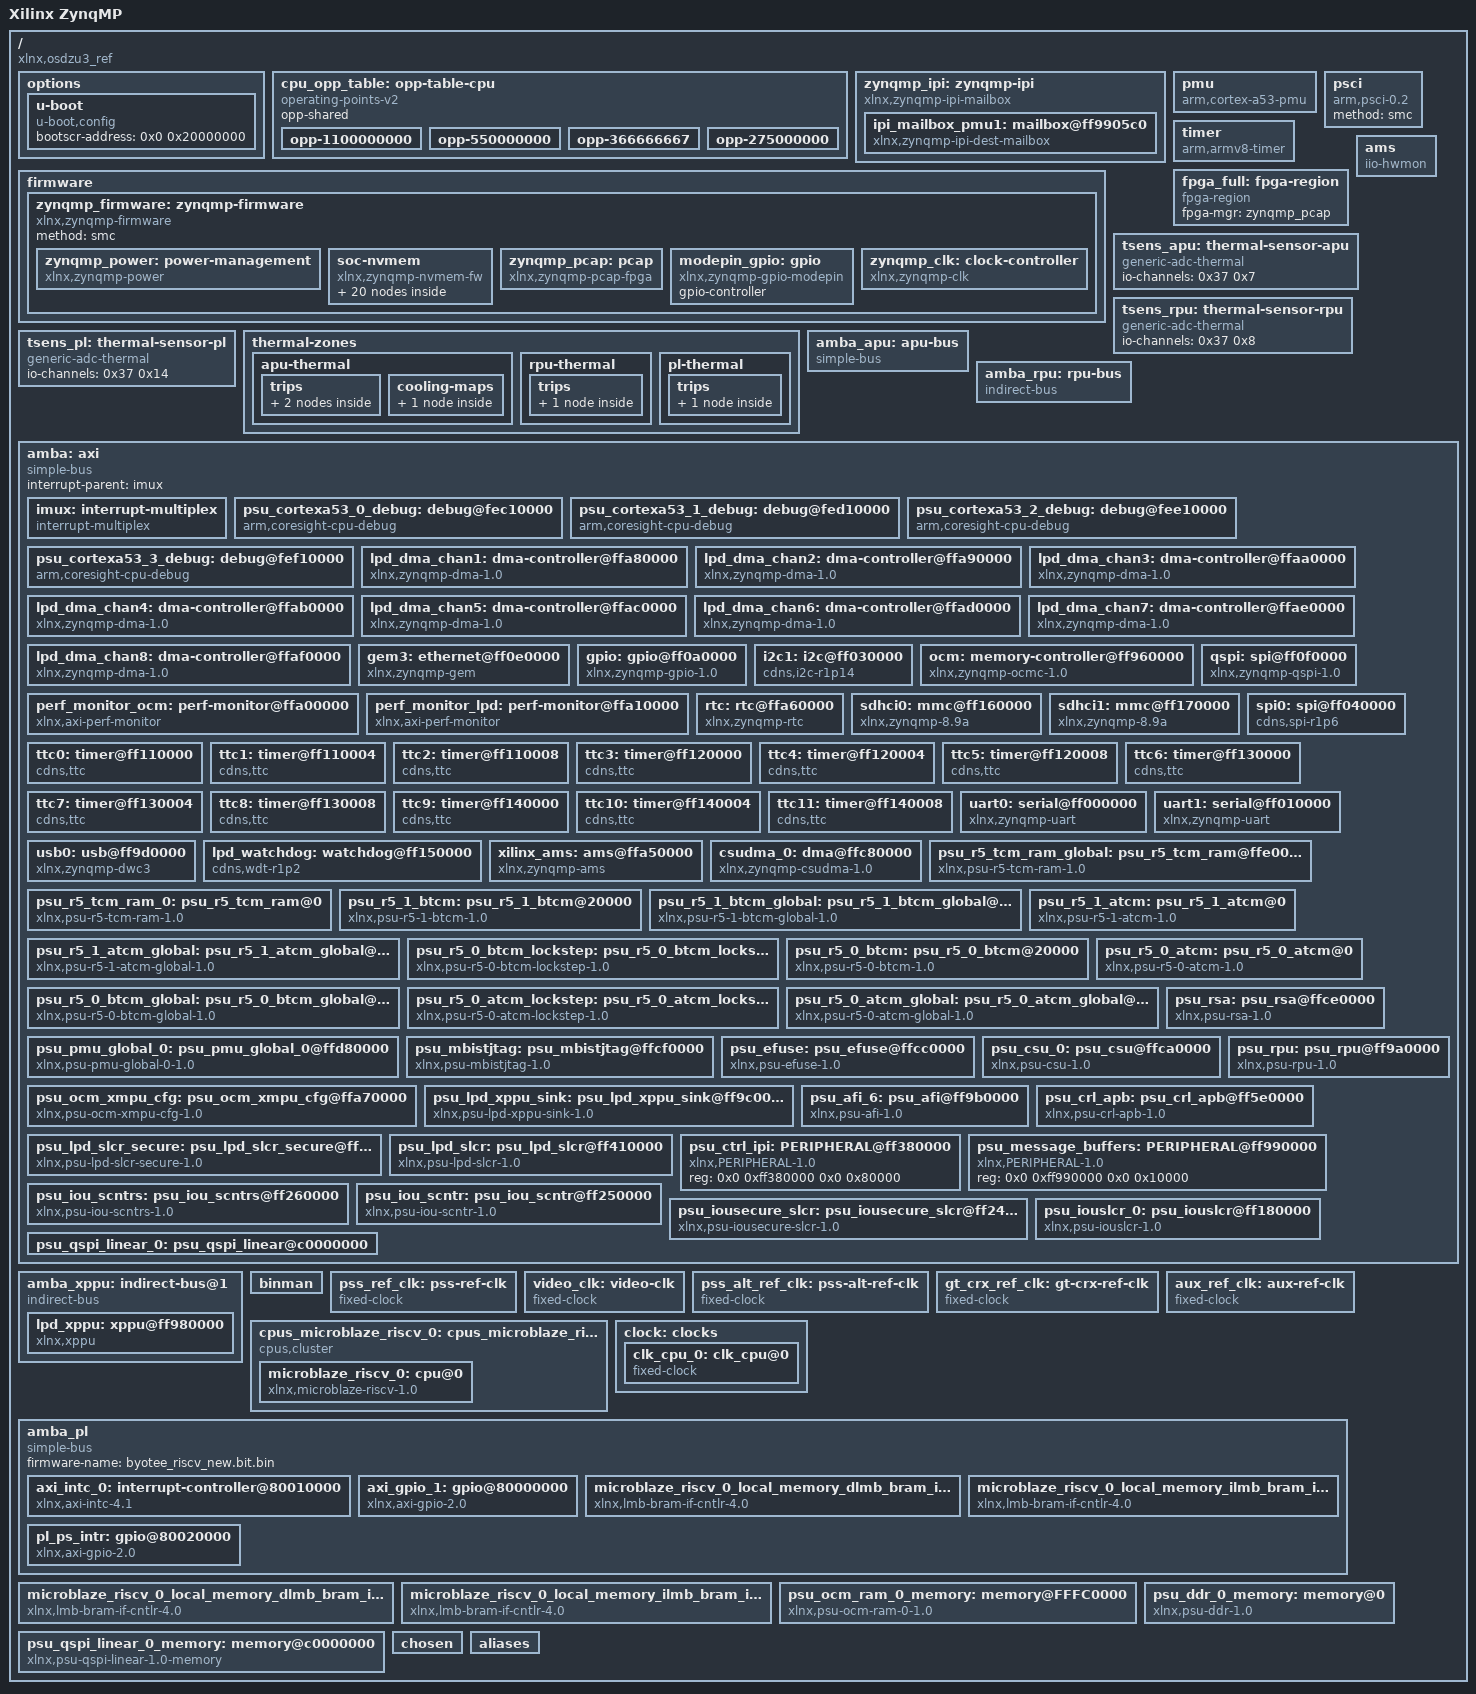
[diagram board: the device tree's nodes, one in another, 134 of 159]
/dts-v1/;
/ {
        compatible = "xlnx,osdzu3_ref";
        #address-cells = <0x2>;
        #size-cells = <0x2>;
        model = "Xilinx ZynqMP";
        board = "osdzu3_ref";
        device_id = "xczu3eg";
        slrcount = <0x1>;
        family = "ZynqMP";
        speed_grade = "1";
        pruned-sdt = <0x1>;

        options {

                u-boot {
                        compatible = "u-boot,config";
                        bootscr-address = <0x0 0x20000000>;
                };
        };

        cpu_opp_table: opp-table-cpu {
                compatible = "operating-points-v2";
                opp-shared;
                phandle = <0x70>;

                opp-1100000000 {
                        opp-hz = <0x0 0x4190ab00>;
                        clock-latency-ns = <0x7a120>;
                        opp-microvolt = <0xf4240>;
                };

                opp-550000000 {
                        opp-hz = <0x0 0x20c85580>;
                        clock-latency-ns = <0x7a120>;
                        opp-microvolt = <0xf4240>;
                };

                opp-366666667 {
                        opp-hz = <0x0 0x15dae3ab>;
                        clock-latency-ns = <0x7a120>;
                        opp-microvolt = <0xf4240>;
                };

                opp-275000000 {
                        opp-hz = <0x0 0x10642ac0>;
                        clock-latency-ns = <0x7a120>;
                        opp-microvolt = <0xf4240>;
                };
        };

        zynqmp_ipi: zynqmp-ipi {
                bootph-all;
                compatible = "xlnx,zynqmp-ipi-mailbox";
                interrupt-parent = <&imux>;
                interrupts = <0x0 0x23 0x4>;
                xlnx,ipi-id = <0x0>;
                #address-cells = <0x2>;
                #size-cells = <0x2>;
                ranges;
                phandle = <0xa8>;

                ipi_mailbox_pmu1: mailbox@ff9905c0 {
                        bootph-all;
                        compatible = "xlnx,zynqmp-ipi-dest-mailbox";
                        reg = <0x0 0xff9905c0 0x0 0x20 0x0 0xff9905e0 0x0 0x20 0x0 0xff990e80 0x0 0x20 0x0 0xff990ea0 0x0 0x20>;
                        reg-names = "local_request_region", "local_response_region", "remote_request_region", "remote_response_region";
                        #mbox-cells = <0x1>;
                        xlnx,ipi-id = <0x4>;
                        phandle = <0x8b>;
                };
        };

        pmu {
                compatible = "arm,cortex-a53-pmu";
                interrupt-parent = <&imux>;
                interrupts = <0x0 0x8f 0x4 0x0 0x90 0x4 0x0 0x91 0x4 0x0 0x92 0x4>;
        };

        psci {
                compatible = "arm,psci-0.2";
                method = "smc";
        };

        firmware {

                zynqmp_firmware: zynqmp-firmware {
                        compatible = "xlnx,zynqmp-firmware";
                        #power-domain-cells = <0x1>;
                        method = "smc";
                        bootph-all;
                        phandle = <0x7b>;

                        zynqmp_power: power-management {
                                bootph-all;
                                compatible = "xlnx,zynqmp-power";
                                interrupt-parent = <&imux>;
                                interrupts = <0x0 0x23 0x4>;
                                mboxes = <0x8b 0x0 0x8b 0x1>;
                                mbox-names = "tx", "rx";
                                phandle = <0xaa>;
                        };

                        soc-nvmem {
                                compatible = "xlnx,zynqmp-nvmem-fw";

                                nvmem-layout {
                                        compatible = "fixed-layout";
                                        #address-cells = <0x1>;
                                        #size-cells = <0x1>;

                                        soc_revision: soc-revision@0 {
                                                reg = <0x0 0x4>;
                                                phandle = <0xab>;
                                        };

                                        efuse_dna: efuse-dna@c {
                                                reg = <0xc 0xc>;
                                                phandle = <0xac>;
                                        };

                                        efuse_usr0: efuse-usr0@20 {
                                                reg = <0x20 0x4>;
                                                phandle = <0xad>;
                                        };

                                        efuse_usr1: efuse-usr1@24 {
                                                reg = <0x24 0x4>;
                                                phandle = <0xae>;
                                        };

                                        efuse_usr2: efuse-usr2@28 {
                                                reg = <0x28 0x4>;
                                                phandle = <0xaf>;
                                        };

                                        efuse_usr3: efuse-usr3@2c {
                                                reg = <0x2c 0x4>;
                                                phandle = <0xb0>;
                                        };

                                        efuse_usr4: efuse-usr4@30 {
                                                reg = <0x30 0x4>;
                                                phandle = <0xb1>;
                                        };

                                        efuse_usr5: efuse-usr5@34 {
                                                reg = <0x34 0x4>;
                                                phandle = <0xb2>;
                                        };

                                        efuse_usr6: efuse-usr6@38 {
                                                reg = <0x38 0x4>;
                                                phandle = <0xb3>;
                                        };

                                        efuse_usr7: efuse-usr7@3c {
                                                reg = <0x3c 0x4>;
                                                phandle = <0xb4>;
                                        };

                                        efuse_miscusr: efuse-miscusr@40 {
                                                reg = <0x40 0x4>;
                                                phandle = <0xb5>;
                                        };

                                        efuse_chash: efuse-chash@50 {
                                                reg = <0x50 0x4>;
                                                phandle = <0xb6>;
                                        };

                                        efuse_pufmisc: efuse-pufmisc@54 {
                                                reg = <0x54 0x4>;
                                                phandle = <0xb7>;
                                        };

                                        efuse_sec: efuse-sec@58 {
                                                reg = <0x58 0x4>;
                                                phandle = <0xb8>;
                                        };

                                        efuse_spkid: efuse-spkid@5c {
                                                reg = <0x5c 0x4>;
                                                phandle = <0xb9>;
                                        };

                                        efuse_aeskey: efuse-aeskey@60 {
                                                reg = <0x60 0x20>;
                                                phandle = <0xba>;
                                        };

                                        efuse_ppk0hash: efuse-ppk0hash@a0 {
                                                reg = <0xa0 0x30>;
                                                phandle = <0xbb>;
                                        };

                                        efuse_ppk1hash: efuse-ppk1hash@d0 {
                                                reg = <0xd0 0x30>;
                                                phandle = <0xbc>;
                                        };

                                        efuse_pufuser: efuse-pufuser@100 {
                                                reg = <0x100 0x7f>;
                                                phandle = <0xbd>;
                                        };
                                };
                        };

                        zynqmp_pcap: pcap {
                                compatible = "xlnx,zynqmp-pcap-fpga";
                                phandle = <0x91>;
                        };

                        modepin_gpio: gpio {
                                compatible = "xlnx,zynqmp-gpio-modepin";
                                gpio-controller;
                                #gpio-cells = <0x2>;
                                phandle = <0x98>;
                        };

                        zynqmp_clk: clock-controller {
                                bootph-all;
                                #clock-cells = <0x1>;
                                compatible = "xlnx,zynqmp-clk";
                                clocks = <&pss_ref_clk>,
                                 <&video_clk>,
                                 <&pss_alt_ref_clk>,
                                 <&aux_ref_clk>,
                                 <&gt_crx_ref_clk>;
                                clock-names = "pss_ref_clk", "video_clk", "pss_alt_ref_clk", "aux_ref_clk", "gt_crx_ref_clk";
                                phandle = <0x73>;
                        };
                };
        };

        timer {
                compatible = "arm,armv8-timer";
                interrupt-parent = <&imux>;
                interrupts = <0x1 0xd 0xf08 0x1 0xe 0xf08 0x1 0xb 0xf08 0x1 0xa 0xf08>;
        };

        fpga_full: fpga-region {
                compatible = "fpga-region";
                fpga-mgr = <&zynqmp_pcap>;
                #address-cells = <0x2>;
                #size-cells = <0x2>;
                ranges;
                phandle = <0xbe>;
        };

        ams {
                compatible = "iio-hwmon";
                io-channels = <0x37 0x0 0x37 0x1 0x37 0x2 0x37 0x3 0x37 0x4 0x37 0x5 0x37 0x6 0x37 0x7 0x37 0x8 0x37 0x9 0x37 0xa 0x37 0xb 0x37 0xc 0x37 0xd 0x37 0xe 0x37 0xf 0x37 0x10 0x37 0x11 0x37 0x12 0x37 0x13 0x37 0x14 0x37 0x15 0x37 0x16 0x37 0x17 0x37 0x18 0x37 0x19 0x37 0x1a 0x37 0x1b 0x37 0x1c 0x37 0x1d>;
        };

        tsens_apu: thermal-sensor-apu {
                compatible = "generic-adc-thermal";
                #thermal-sensor-cells = <0x0>;
                io-channels = <0x37 0x7>;
                io-channel-names = "sensor-channel";
                phandle = <0x92>;
        };

        tsens_rpu: thermal-sensor-rpu {
                compatible = "generic-adc-thermal";
                #thermal-sensor-cells = <0x0>;
                io-channels = <0x37 0x8>;
                io-channel-names = "sensor-channel";
                phandle = <0x94>;
        };

        tsens_pl: thermal-sensor-pl {
                compatible = "generic-adc-thermal";
                #thermal-sensor-cells = <0x0>;
                io-channels = <0x37 0x14>;
                io-channel-names = "sensor-channel";
                phandle = <0x95>;
        };

        thermal-zones {

                apu-thermal {
                        polling-delay-passive = <0x3e8>;
                        polling-delay = <0x1388>;
                        thermal-sensors = <0x92>;

                        trips {

                                apu_passive: passive {
                                        temperature = <0x16b48>;
                                        hysteresis = <0xdac>;
                                        type = "passive";
                                        phandle = <0x93>;
                                };

                                apu_critical: critical {
                                        temperature = <0x178f4>;
                                        hysteresis = <0xdac>;
                                        type = "critical";
                                        phandle = <0xbf>;
                                };
                        };

                        cooling-maps {

                                map {
                                        trip = <0x93>;
                                        cooling-device = <0x87 0xffffffff 0xffffffff 0x88 0xffffffff 0xffffffff 0x89 0xffffffff 0xffffffff 0x8a 0xffffffff 0xffffffff>;
                                };
                        };
                };

                rpu-thermal {
                        polling-delay = <0x2710>;
                        thermal-sensors = <0x94>;

                        trips {

                                critical {
                                        temperature = <0x178f4>;
                                        hysteresis = <0xdac>;
                                        type = "critical";
                                };
                        };
                };

                pl-thermal {
                        polling-delay = <0x2710>;
                        thermal-sensors = <0x95>;

                        trips {

                                critical {
                                        temperature = <0x178f4>;
                                        hysteresis = <0xdac>;
                                        type = "critical";
                                };
                        };
                };
        };

        amba_apu: apu-bus {
                compatible = "simple-bus";
                #address-cells = <0x2>;
                #size-cells = <0x2>;
                ranges;
                phandle = <0x2>;
        };

        amba_rpu: rpu-bus {
                compatible = "indirect-bus";
                #address-cells = <0x2>;
                #size-cells = <0x1>;
                phandle = <0x74>;
        };

        amba: axi {
                compatible = "simple-bus";
                bootph-all;
                #address-cells = <0x2>;
                #size-cells = <0x2>;
                ranges;
                interrupt-parent = <&imux>;
                phandle = <0x1>;

                imux: interrupt-multiplex {
                        compatible = "interrupt-multiplex";
                        #address-cells = <0x0>;
                        #interrupt-cells = <0x3>;
                        interrupt-controller;
                        interrupt-map-mask = <0x0 0xffff 0x0>;
                        interrupt-map = <0x0 0x17 0x0 0x41 0x0 0x17 0x1 0x0 0x18 0x0 0x41 0x0 0x18 0x1 0x0 0x7b 0x0 0x41 0x0 0x7b 0x4 0x0 0x56 0x0 0x41 0x0 0x56 0x4 0x0 0x7c 0x0 0x41 0x0 0x7c 0x4 0x0 0x7d 0x0 0x41 0x0 0x7d 0x4 0x0 0x7e 0x0 0x41 0x0 0x8e 0x4 0x0 0x7f 0x0 0x41 0x0 0x7f 0x4 0x0 0x80 0x0 0x41 0x0 0x80 0x4 0x0 0x81 0x0 0x41 0x0 0x81 0x4 0x0 0x82 0x0 0x41 0x0 0x82 0x4 0x0 0x83 0x0 0x41 0x0 0x83 0x4 0x0 0x84 0x0 0x41 0x0 0x84 0x4 0x0 0x4d 0x0 0x41 0x0 0x4d 0x4 0x0 0x4e 0x0 0x41 0x0 0x4e 0x4 0x0 0x4f 0x0 0x41 0x0 0x4f 0x4 0x0 0x50 0x0 0x41 0x0 0x50 0x4 0x0 0x51 0x0 0x41 0x0 0x51 0x4 0x0 0x52 0x0 0x41 0x0 0x52 0x4 0x0 0x53 0x0 0x41 0x0 0x53 0x4 0x0 0x54 0x0 0x41 0x0 0x54 0x4 0x0 0x70 0x0 0x41 0x0 0x70 0x4 0x0 0xe 0x0 0x41 0x0 0xe 0x4 0x0 0x39 0x0 0x41 0x0 0x39 0x4 0x0 0x3b 0x0 0x41 0x0 0x3b 0x4 0x0 0x3d 0x0 0x41 0x0 0x3d 0x4 0x0 0x3f 0x0 0x41 0x0 0x3f 0x4 0x0 0x10 0x0 0x41 0x0 0x10 0x4 0x0 0x11 0x0 0x41 0x0 0x11 0x4 0x0 0x12 0x0 0x41 0x0 0x12 0x4 0x0 0xa 0x0 0x41 0x0 0xa 0x4 0x0 0x72 0x0 0x41 0x0 0x72 0x4 0x0 0x73 0x0 0x41 0x0 0x73 0x4 0x0 0x74 0x0 0x41 0x0 0x74 0x1 0x0 0x75 0x0 0x41 0x0 0x75 0x1 0x0 0x76 0x0 0x41 0x0 0x76 0x4 0x0 0xf 0x0 0x41 0x0 0xf 0x4 0x0 0x1a 0x0 0x41 0x0 0x1a 0x4 0x0 0x1b 0x0 0x41 0x0 0x1b 0x4 0x0 0x85 0x0 0x41 0x0 0x85 0x4 0x0 0x30 0x0 0x41 0x0 0x30 0x4 0x0 0x31 0x0 0x41 0x0 0x31 0x4 0x0 0x13 0x0 0x41 0x0 0x13 0x4 0x0 0x14 0x0 0x41 0x0 0x14 0x4 0x0 0x24 0x0 0x41 0x0 0x24 0x4 0x0 0x25 0x0 0x41 0x0 0x25 0x4 0x0 0x26 0x0 0x41 0x0 0x26 0x4 0x0 0x27 0x0 0x41 0x0 0x27 0x4 0x0 0x28 0x0 0x41 0x0 0x28 0x4 0x0 0x29 0x0 0x41 0x0 0x29 0x4 0x0 0x2a 0x0 0x41 0x0 0x2a 0x4 0x0 0x2b 0x0 0x41 0x0 0x2b 0x4 0x0 0x2c 0x0 0x41 0x0 0x2c 0x4 0x0 0x2d 0x0 0x41 0x0 0x2d 0x4 0x0 0x2e 0x0 0x41 0x0 0x2e 0x4 0x0 0x2f 0x0 0x41 0x0 0x2f 0x4 0x0 0x15 0x0 0x41 0x0 0x15 0x4 0x0 0x16 0x0 0x41 0x0 0x16 0x4 0x0 0x41 0x0 0x41 0x0 0x41 0x4 0x0 0x45 0x0 0x41 0x0 0x45 0x4 0x0 0x4b 0x0 0x41 0x0 0x4b 0x4 0x0 0x46 0x0 0x41 0x0 0x46 0x4 0x0 0x4a 0x0 0x41 0x0 0x4a 0x4 0x0 0x4c 0x0 0x41 0x0 0x4c 0x4 0x0 0x35 0x0 0x41 0x0 0x35 0x4 0x0 0x71 0x0 0x41 0x0 0x71 0x4 0x0 0x77 0x0 0x41 0x0 0x77 0x4 0x0 0x1d 0x0 0x41 0x0 0x1d 0x4 0x0 0x1e 0x0 0x41 0x0 0x1e 0x4 0x0 0x1f 0x0 0x41 0x0 0x1f 0x4 0x0 0x20 0x0 0x41 0x0 0x20 0x4 0x0 0x21 0x0 0x41 0x0 0x21 0x4 0x0 0x22 0x0 0x41 0x0 0x22 0x4 0x0 0x23 0x0 0x41 0x0 0x23 0x4 0x0 0x7a 0x0 0x41 0x0 0x7a 0x4 0x0 0x17 0x0 0x7a 0x0 0x17 0x1 0x0 0x18 0x0 0x7a 0x0 0x18 0x1 0x0 0x7b 0x0 0x7a 0x0 0x7b 0x4 0x0 0x56 0x0 0x7a 0x0 0x56 0x4 0x0 0x7c 0x0 0x7a 0x0 0x7c 0x4 0x0 0x7d 0x0 0x7a 0x0 0x7d 0x4 0x0 0x7e 0x0 0x7a 0x0 0x8e 0x4 0x0 0x7f 0x0 0x7a 0x0 0x7f 0x4 0x0 0x80 0x0 0x7a 0x0 0x80 0x4 0x0 0x81 0x0 0x7a 0x0 0x81 0x4 0x0 0x82 0x0 0x7a 0x0 0x82 0x4 0x0 0x83 0x0 0x7a 0x0 0x83 0x4 0x0 0x84 0x0 0x7a 0x0 0x84 0x4 0x0 0x4d 0x0 0x7a 0x0 0x4d 0x4 0x0 0x4e 0x0 0x7a 0x0 0x4e 0x4 0x0 0x4f 0x0 0x7a 0x0 0x4f 0x4 0x0 0x50 0x0 0x7a 0x0 0x50 0x4 0x0 0x51 0x0 0x7a 0x0 0x51 0x4 0x0 0x52 0x0 0x7a 0x0 0x52 0x4 0x0 0x53 0x0 0x7a 0x0 0x53 0x4 0x0 0x54 0x0 0x7a 0x0 0x54 0x4 0x0 0x70 0x0 0x7a 0x0 0x70 0x4 0x0 0xe 0x0 0x7a 0x0 0xe 0x4 0x0 0x39 0x0 0x7a 0x0 0x39 0x4 0x0 0x3b 0x0 0x7a 0x0 0x3b 0x4 0x0 0x3d 0x0 0x7a 0x0 0x3d 0x4 0x0 0x3f 0x0 0x7a 0x0 0x3f 0x4 0x0 0x10 0x0 0x7a 0x0 0x10 0x4 0x0 0x11 0x0 0x7a 0x0 0x11 0x4 0x0 0x12 0x0 0x7a 0x0 0x12 0x4 0x0 0xa 0x0 0x7a 0x0 0xa 0x4 0x0 0x72 0x0 0x7a 0x0 0x72 0x4 0x0 0x73 0x0 0x7a 0x0 0x73 0x4 0x0 0x74 0x0 0x7a 0x0 0x74 0x1 0x0 0x75 0x0 0x7a 0x0 0x75 0x1 0x0 0x76 0x0 0x7a 0x0 0x76 0x4 0x0 0xf 0x0 0x7a 0x0 0xf 0x4 0x0 0x1a 0x0 0x7a 0x0 0x1a 0x4 0x0 0x1b 0x0 0x7a 0x0 0x1b 0x4 0x0 0x85 0x0 0x7a 0x0 0x85 0x4 0x0 0x30 0x0 0x7a 0x0 0x30 0x4 0x0 0x31 0x0 0x7a 0x0 0x31 0x4 0x0 0x13 0x0 0x7a 0x0 0x13 0x4 0x0 0x14 0x0 0x7a 0x0 0x14 0x4 0x0 0x24 0x0 0x7a 0x0 0x24 0x4 0x0 0x25 0x0 0x7a 0x0 0x25 0x4 0x0 0x26 0x0 0x7a 0x0 0x26 0x4 0x0 0x27 0x0 0x7a 0x0 0x27 0x4 0x0 0x28 0x0 0x7a 0x0 0x28 0x4 0x0 0x29 0x0 0x7a 0x0 0x29 0x4 0x0 0x2a 0x0 0x7a 0x0 0x2a 0x4 0x0 0x2b 0x0 0x7a 0x0 0x2b 0x4 0x0 0x2c 0x0 0x7a 0x0 0x2c 0x4 0x0 0x2d 0x0 0x7a 0x0 0x2d 0x4 0x0 0x2e 0x0 0x7a 0x0 0x2e 0x4 0x0 0x2f 0x0 0x7a 0x0 0x2f 0x4 0x0 0x15 0x0 0x7a 0x0 0x15 0x4 0x0 0x16 0x0 0x7a 0x0 0x16 0x4 0x0 0x41 0x0 0x7a 0x0 0x41 0x4 0x0 0x45 0x0 0x7a 0x0 0x45 0x4 0x0 0x4b 0x0 0x7a 0x0 0x4b 0x4 0x0 0x46 0x0 0x7a 0x0 0x46 0x4 0x0 0x4a 0x0 0x7a 0x0 0x4a 0x4 0x0 0x4c 0x0 0x7a 0x0 0x4c 0x4 0x0 0x35 0x0 0x7a 0x0 0x35 0x4 0x0 0x71 0x0 0x7a 0x0 0x71 0x4 0x0 0x77 0x0 0x7a 0x0 0x77 0x4 0x0 0x1d 0x0 0x7a 0x0 0x1d 0x4 0x0 0x1e 0x0 0x7a 0x0 0x1e 0x4 0x0 0x1f 0x0 0x7a 0x0 0x1f 0x4 0x0 0x20 0x0 0x7a 0x0 0x20 0x4 0x0 0x21 0x0 0x7a 0x0 0x21 0x4 0x0 0x22 0x0 0x7a 0x0 0x22 0x4 0x0 0x23 0x0 0x7a 0x0 0x23 0x4 0x0 0x7a 0x0 0x7a 0x0 0x7a 0x4>;
                        phandle = <0x86>;
                };

                psu_cortexa53_0_debug: debug@fec10000 {
                        compatible = "arm,coresight-cpu-debug", "arm,primecell";
                        reg = <0x0 0xfec10000 0x0 0x1000>;
                        clock-names = "apb_pclk";
                        cpu = <0x87>;
                        clocks = <&zynqmp_clk 0xc>;
                        phandle = <0xc3>;
                };

                psu_cortexa53_1_debug: debug@fed10000 {
                        compatible = "arm,coresight-cpu-debug", "arm,primecell";
                        reg = <0x0 0xfed10000 0x0 0x1000>;
                        clock-names = "apb_pclk";
                        cpu = <0x88>;
                        clocks = <&zynqmp_clk 0xc>;
                        phandle = <0xc4>;
                };

                psu_cortexa53_2_debug: debug@fee10000 {
                        compatible = "arm,coresight-cpu-debug", "arm,primecell";
                        reg = <0x0 0xfee10000 0x0 0x1000>;
                        clock-names = "apb_pclk";
                        cpu = <0x89>;
                        clocks = <&zynqmp_clk 0xc>;
                        phandle = <0xc5>;
                };

                psu_cortexa53_3_debug: debug@fef10000 {
                        compatible = "arm,coresight-cpu-debug", "arm,primecell";
                        reg = <0x0 0xfef10000 0x0 0x1000>;
                        clock-names = "apb_pclk";
                        cpu = <0x8a>;
                        clocks = <&zynqmp_clk 0xc>;
                        phandle = <0xc6>;
                };

                lpd_dma_chan1: dma-controller@ffa80000 {
                        status = "okay";
                        compatible = "xlnx,zynqmp-dma-1.0";
                        reg = <0x0 0xffa80000 0x0 0x1000>;
                        interrupt-parent = <&imux>;
                        interrupts = <0x0 0x4d 0x4>;
                        clock-names = "clk_main", "clk_apb";
                        #dma-cells = <0x1>;
                        xlnx,bus-width = <0x40>;
                        power-domains = <&zynqmp_firmware 0x2b>;
                        clocks = <&zynqmp_clk 0x44>,
                         <&zynqmp_clk 0x1f>;
                        xlnx,is-cache-coherent = <0x0>;
                        xlnx,ip-name = "psu_adma";
                        xlnx,dma-mode = <0x1>;
                        xlnx,dma-type = <0x1>;
                        xlnx,name = "psu_adma_0";
                        phandle = <0x34>;
                };

                lpd_dma_chan2: dma-controller@ffa90000 {
                        status = "okay";
                        compatible = "xlnx,zynqmp-dma-1.0";
                        reg = <0x0 0xffa90000 0x0 0x1000>;
                        interrupt-parent = <&imux>;
                        interrupts = <0x0 0x4e 0x4>;
                        clock-names = "clk_main", "clk_apb";
                        #dma-cells = <0x1>;
                        xlnx,bus-width = <0x40>;
                        power-domains = <&zynqmp_firmware 0x2b>;
                        clocks = <&zynqmp_clk 0x44>,
                         <&zynqmp_clk 0x1f>;
                        xlnx,is-cache-coherent = <0x0>;
                        xlnx,ip-name = "psu_adma";
                        xlnx,dma-mode = <0x1>;
                        xlnx,dma-type = <0x1>;
                        xlnx,name = "psu_adma_1";
                        phandle = <0x33>;
                };

                lpd_dma_chan3: dma-controller@ffaa0000 {
                        status = "okay";
                        compatible = "xlnx,zynqmp-dma-1.0";
                        reg = <0x0 0xffaa0000 0x0 0x1000>;
                        interrupt-parent = <&imux>;
                        interrupts = <0x0 0x4f 0x4>;
                        clock-names = "clk_main", "clk_apb";
                        #dma-cells = <0x1>;
                        xlnx,bus-width = <0x40>;
                        power-domains = <&zynqmp_firmware 0x2b>;
                        clocks = <&zynqmp_clk 0x44>,
                         <&zynqmp_clk 0x1f>;
                        xlnx,is-cache-coherent = <0x0>;
                        xlnx,ip-name = "psu_adma";
                        xlnx,dma-mode = <0x1>;
                        xlnx,dma-type = <0x1>;
                        xlnx,name = "psu_adma_2";
                        phandle = <0x32>;
                };

                lpd_dma_chan4: dma-controller@ffab0000 {
                        status = "okay";
                        compatible = "xlnx,zynqmp-dma-1.0";
                        reg = <0x0 0xffab0000 0x0 0x1000>;
                        interrupt-parent = <&imux>;
                        interrupts = <0x0 0x50 0x4>;
                        clock-names = "clk_main", "clk_apb";
                        #dma-cells = <0x1>;
                        xlnx,bus-width = <0x40>;
                        power-domains = <&zynqmp_firmware 0x2b>;
                        clocks = <&zynqmp_clk 0x44>,
                         <&zynqmp_clk 0x1f>;
                        xlnx,is-cache-coherent = <0x0>;
                        xlnx,ip-name = "psu_adma";
                        xlnx,dma-mode = <0x1>;
                        xlnx,dma-type = <0x1>;
                        xlnx,name = "psu_adma_3";
                        phandle = <0x31>;
                };

                lpd_dma_chan5: dma-controller@ffac0000 {
                        status = "okay";
                        compatible = "xlnx,zynqmp-dma-1.0";
                        reg = <0x0 0xffac0000 0x0 0x1000>;
                        interrupt-parent = <&imux>;
                        interrupts = <0x0 0x51 0x4>;
                        clock-names = "clk_main", "clk_apb";
                        #dma-cells = <0x1>;
                        xlnx,bus-width = <0x40>;
                        power-domains = <&zynqmp_firmware 0x2b>;
                        clocks = <&zynqmp_clk 0x44>,
                         <&zynqmp_clk 0x1f>;
                        xlnx,is-cache-coherent = <0x0>;
                        xlnx,ip-name = "psu_adma";
                        xlnx,dma-mode = <0x1>;
                        xlnx,dma-type = <0x1>;
                        xlnx,name = "psu_adma_4";
                        phandle = <0x30>;
                };

                lpd_dma_chan6: dma-controller@ffad0000 {
                        status = "okay";
                        compatible = "xlnx,zynqmp-dma-1.0";
                        reg = <0x0 0xffad0000 0x0 0x1000>;
                        interrupt-parent = <&imux>;
                        interrupts = <0x0 0x52 0x4>;
                        clock-names = "clk_main", "clk_apb";
                        #dma-cells = <0x1>;
                        xlnx,bus-width = <0x40>;
                        power-domains = <&zynqmp_firmware 0x2b>;
                        clocks = <&zynqmp_clk 0x44>,
                         <&zynqmp_clk 0x1f>;
                        xlnx,is-cache-coherent = <0x0>;
                        xlnx,ip-name = "psu_adma";
                        xlnx,dma-mode = <0x1>;
                        xlnx,dma-type = <0x1>;
                        xlnx,name = "psu_adma_5";
                        phandle = <0x2f>;
                };

                lpd_dma_chan7: dma-controller@ffae0000 {
                        status = "okay";
                        compatible = "xlnx,zynqmp-dma-1.0";
                        reg = <0x0 0xffae0000 0x0 0x1000>;
                        interrupt-parent = <&imux>;
                        interrupts = <0x0 0x53 0x4>;
                        clock-names = "clk_main", "clk_apb";
                        #dma-cells = <0x1>;
                        xlnx,bus-width = <0x40>;
                        power-domains = <&zynqmp_firmware 0x2b>;
                        clocks = <&zynqmp_clk 0x44>,
                         <&zynqmp_clk 0x1f>;
                        xlnx,is-cache-coherent = <0x0>;
                        xlnx,ip-name = "psu_adma";
                        xlnx,dma-mode = <0x1>;
                        xlnx,dma-type = <0x1>;
                        xlnx,name = "psu_adma_6";
                        phandle = <0x2e>;
                };

                lpd_dma_chan8: dma-controller@ffaf0000 {
                        status = "okay";
                        compatible = "xlnx,zynqmp-dma-1.0";
                        reg = <0x0 0xffaf0000 0x0 0x1000>;
                        interrupt-parent = <&imux>;
                        interrupts = <0x0 0x54 0x4>;
                        clock-names = "clk_main", "clk_apb";
                        #dma-cells = <0x1>;
                        xlnx,bus-width = <0x40>;
                        power-domains = <&zynqmp_firmware 0x2b>;
                        clocks = <&zynqmp_clk 0x44>,
                         <&zynqmp_clk 0x1f>;
                        xlnx,is-cache-coherent = <0x0>;
                        xlnx,ip-name = "psu_adma";
                        xlnx,dma-mode = <0x1>;
                        xlnx,dma-type = <0x1>;
                        xlnx,name = "psu_adma_7";
                        phandle = <0x2d>;
                };

                gem3: ethernet@ff0e0000 {
                        compatible = "xlnx,zynqmp-gem", "cdns,gem";
                        status = "okay";
                        interrupt-parent = <&imux>;
                        interrupts = <0x0 0x3f 0x4 0x0 0x3f 0x4>;
                        reg = <0x0 0xff0e0000 0x0 0x1000>;
                        clock-names = "pclk", "hclk", "tx_clk", "rx_clk", "tsu_clk";
                        power-domains = <&zynqmp_firmware 0x20>;
                        reset-names = "gem3_rst";
                        clocks = <&zynqmp_clk 0x1f>,
                         <&zynqmp_clk 0x6b>,
                         <&zynqmp_clk 0x30>,
                         <&zynqmp_clk 0x34>,
                         <&zynqmp_clk 0x2c>;
                        assigned-clocks = <&zynqmp_clk 0x2c>;
                        xlnx,is-cache-coherent = <0x0>;
                        xlnx,has-mdio = <0x2faf080>;
                        xlnx,gem-board-interface = "custom";
                        phy-mode = "rgmii-id";
                        xlnx,tz-nonsecure = <0x1>;
                        xlnx,enet-slcr-1000mbps-div0 = <0xc>;
                        xlnx,enet-slcr-10mbps-div0 = <0x3c>;
                        xlnx,enet-slcr-1000mbps-div1 = <0x1>;
                        xlnx,enet-slcr-10mbps-div1 = <0xa>;
                        xlnx,enet-tsu-clk-freq-hz = <0xee6a8ba>;
                        xlnx,ip-name = "psu_ethernet";
                        xlnx,eth-mode = <0x1>;
                        xlnx,enet-reset = <0x2faf080>;
                        xlnx,enet-clk-freq-hz = <0x773545d>;
                        xlnx,enet-slcr-100mbps-div0 = <0x3c>;
                        xlnx,enet-slcr-100mbps-div1 = <0x1>;
                        xlnx,name = "psu_ethernet_3";
                        phandle = <0x1b>;
                };

                gpio: gpio@ff0a0000 {
                        compatible = "xlnx,zynqmp-gpio-1.0";
                        status = "okay";
                        #gpio-cells = <0x2>;
                        gpio-controller;
                        interrupt-parent = <&imux>;
                        interrupts = <0x0 0x10 0x4>;
                        interrupt-controller;
                        #interrupt-cells = <0x2>;
                        reg = <0x0 0xff0a0000 0x0 0x1000>;
                        power-domains = <&zynqmp_firmware 0x2e>;
                        clocks = <&zynqmp_clk 0x1f>;
                        xlnx,gpio-board-interface = "custom";
                        xlnx,mio-gpio-mask = <0x5600>;
                        gpio-mask-high = <0x0>;
                        xlnx,emio-gpio-width = <0x20>;
                        xlnx,ip-name = "psu_gpio";
                        gpio-mask-low = <0x5600>;
                        emio-gpio-width = <0x20>;
                        xlnx,name = "psu_gpio_0";
                        phandle = <0x1c>;
                };

                i2c1: i2c@ff030000 {
                        compatible = "cdns,i2c-r1p14";
                        status = "okay";
                        interrupt-parent = <&imux>;
                        interrupts = <0x0 0x12 0x4>;
                        clock-frequency = <0x61a80>;
                        reg = <0x0 0xff030000 0x0 0x1000>;
                        #address-cells = <0x1>;
                        #size-cells = <0x0>;
                        power-domains = <&zynqmp_firmware 0x26>;
                        clocks = <&zynqmp_clk 0x3e>;
                        xlnx,i2c-reset = <0x0>;
                        xlnx,has-interrupt = <0x2faf080>;
                        xlnx,clock-freq = <0x5f5dd19>;
                        xlnx,i2c-clk-freq-hz = <0x5f5dd19>;
                        xlnx,ip-name = "psu_i2c";
                        xlnx,iic-board-interface = "custom";
                        xlnx,name = "psu_i2c_1";
                        phandle = <0x1e>;
                };

                ocm: memory-controller@ff960000 {
                        compatible = "xlnx,zynqmp-ocmc-1.0";
                        reg = <0x0 0xff960000 0x0 0x1000>;
                        interrupt-parent = <&imux>;
                        interrupts = <0x0 0xa 0x4>;
                        status = "okay";
                        xlnx,ip-name = "psu_ocm";
                        xlnx,name = "psu_ocm";
                        phandle = <0x23>;
                };

                perf_monitor_ocm: perf-monitor@ffa00000 {
                        compatible = "xlnx,axi-perf-monitor";
                        reg = <0x0 0xffa00000 0x0 0x10000>;
                        interrupts = <0x0 0x19 0x4>;
                        interrupt-parent = <&imux>;
                        xlnx,enable-profile = <0x0>;
                        xlnx,enable-trace = <0x0>;
                        xlnx,num-monitor-slots = <0x1>;
                        xlnx,enable-event-count = <0x1>;
                        xlnx,enable-event-log = <0x0>;
                        xlnx,have-sampled-metric-cnt = <0x1>;
                        xlnx,num-of-counters = <0x3>;
                        xlnx,metric-count-width = <0x20>;
                        xlnx,metrics-sample-count-width = <0x20>;
                        xlnx,global-count-width = <0x20>;
                        xlnx,metric-count-scale = <0x1>;
                        clocks = <&zynqmp_clk 0x1f>;
                        xlnx,enable-32bit-filter-id = <0x1>;
                        xlnx,ip-name = "psu_apm";
                        xlnx,fifo-axis-tid-width = <0x1>;
                        xlnx,enable-advanced = <0x1>;
                        xlnx,can-clk-freq-hz = <0x2faf080>;
                        status = "okay";
                        xlnx,fifo-axis-tdata-width = <0x38>;
                        xlnx,fifo-axis-depth = <0x20>;
                        xlnx,name = "psu_apm_1";
                        phandle = <0x39>;
                };

                perf_monitor_lpd: perf-monitor@ffa10000 {
                        compatible = "xlnx,axi-perf-monitor";
                        reg = <0x0 0xffa10000 0x0 0x10000>;
                        interrupts = <0x0 0x19 0x4>;
                        interrupt-parent = <&imux>;
                        xlnx,enable-profile = <0x0>;
                        xlnx,enable-trace = <0x0>;
                        xlnx,num-monitor-slots = <0x1>;
                        xlnx,enable-event-count = <0x1>;
                        xlnx,enable-event-log = <0x0>;
                        xlnx,have-sampled-metric-cnt = <0x1>;
                        xlnx,num-of-counters = <0x3>;
                        xlnx,metric-count-width = <0x20>;
                        xlnx,metrics-sample-count-width = <0x20>;
                        xlnx,global-count-width = <0x20>;
                        xlnx,metric-count-scale = <0x1>;
                        clocks = <&zynqmp_clk 0x1f>;
                        xlnx,enable-32bit-filter-id = <0x1>;
                        xlnx,ip-name = "psu_apm";
                        xlnx,fifo-axis-tid-width = <0x1>;
                        xlnx,enable-advanced = <0x1>;
                        xlnx,can-clk-freq-hz = <0x2faf080>;
                        status = "okay";
                        xlnx,fifo-axis-tdata-width = <0x38>;
                        xlnx,fifo-axis-depth = <0x20>;
                        xlnx,name = "psu_apm_2";
                        phandle = <0x38>;
                };

                qspi: spi@ff0f0000 {
                        bootph-all;
                        compatible = "xlnx,zynqmp-qspi-1.0";
                        status = "okay";
                        clock-names = "ref_clk", "pclk";
                        interrupts = <0x0 0xf 0x4>;
                        interrupt-parent = <&imux>;
                        num-cs = <0x2>;
                        reg = <0x0 0xff0f0000 0x0 0x1000 0x0 0xc0000000 0x0 0x8000000>;
                        #address-cells = <0x1>;
                        #size-cells = <0x0>;
                        power-domains = <&zynqmp_firmware 0x2d>;
                        clocks = <&zynqmp_clk 0x35>,
                         <&zynqmp_clk 0x1f>;
                        xlnx,is-cache-coherent = <0x0>;
                        xlnx,qspi-fbclk = <0x0>;
                        xlnx,tz-nonsecure = <0x1>;
                        xlnx,qspi-clk-freq-hz = <0x773545d>;
                        xlnx,bus-width = <0x2>;
                        xlnx,ip-name = "psu_qspi";
                        xlnx,qspi-board-interface = "custom";
                        spi-rx-bus-width = <0x4>;
                        xlnx,connection-mode = <0x2>;
                        spi-tx-bus-width = <0x4>;
                        xlnx,clock-freq = <0x773545d>;
                        xlnx,fb-clk = <0x1>;
                        xlnx,qspi-mode = <0x2>;
                        xlnx,name = "psu_qspi_0";
                        xlnx,qspi-bus-width = <0x2>;
                        is-dual = <0x1>;
                        phandle = <0x1a>;
                };

                rtc: rtc@ffa60000 {
                        compatible = "xlnx,zynqmp-rtc";
                        status = "okay";
                        reg = <0x0 0xffa60000 0x0 0x100>;
                        interrupt-parent = <&imux>;
                        interrupts = <0x0 0x1a 0x4 0x0 0x1b 0x4>;
                        interrupt-names = "alarm", "sec";
                        calibration = <0x7fff>;
                        xlnx,ip-name = "psu_rtc";
                        xlnx,name = "psu_rtc";
                        phandle = <0x36>;
                };

                sdhci0: mmc@ff160000 {
                        bootph-all;
                        compatible = "xlnx,zynqmp-8.9a", "arasan,sdhci-8.9a";
                        status = "okay";
                        interrupt-parent = <&imux>;
                        interrupts = <0x0 0x30 0x4>;
                        reg = <0x0 0xff160000 0x0 0x1000>;
                        clock-names = "clk_xin", "clk_ahb";
                        #clock-cells = <0x1>;
                        clock-output-names = "clk_out_sd0", "clk_in_sd0";
                        power-domains = <&zynqmp_firmware 0x27>;
                        clocks = <&zynqmp_clk 0x36>,
                         <&zynqmp_clk 0x1f>;
                        assigned-clocks = <&zynqmp_clk 0x36>;
                        xlnx,sd-board-interface = "custom";
                        xlnx,is-cache-coherent = <0x0>;
                        xlnx,clk-50-ddr-otap-dly = <0x6>;
                        xlnx,clk-50-sdr-itap-dly = <0x15>;
                        xlnx,has-emio = <0x0>;
                        clock-frequency = <0xbebba31>;
                        xlnx,tz-nonsecure = <0x1>;
                        xlnx,clk-100-sdr-otap-dly = <0x0>;
                        xlnx,mio-bank = <0x0>;
                        xlnx,ip-name = "psu_sd";
                        xlnx,bus-width = <0x8>;
                        xlnx,card-detect = <0x0>;
                        xlnx,has-wp = <0x0>;
                        xlnx,has-cd = <0x0>;
                        xlnx,slot-type = <0x1>;
                        xlnx,clk-50-sdr-otap-dly = <0x6>;
                        xlnx,clk-50-ddr-itap-dly = <0x12>;
                        xlnx,has-power = <0x0>;
                        xlnx,clk-200-sdr-otap-dly = <0x3>;
                        xlnx,sdio-clk-freq-hz = <0xbebba31>;
                        xlnx,write-protect = <0x0>;
                        xlnx,name = "psu_sd_0";
                        phandle = <0x14>;
                };

                sdhci1: mmc@ff170000 {
                        bootph-all;
                        compatible = "xlnx,zynqmp-8.9a", "arasan,sdhci-8.9a";
                        status = "okay";
                        interrupt-parent = <&imux>;
                        interrupts = <0x0 0x31 0x4>;
                        reg = <0x0 0xff170000 0x0 0x1000>;
                        clock-names = "clk_xin", "clk_ahb";
                        #clock-cells = <0x1>;
                        clock-output-names = "clk_out_sd1", "clk_in_sd1";
                        power-domains = <&zynqmp_firmware 0x28>;
                        clocks = <&zynqmp_clk 0x37>,
                         <&zynqmp_clk 0x1f>;
                        assigned-clocks = <&zynqmp_clk 0x37>;
                        xlnx,sd-board-interface = "custom";
                        xlnx,is-cache-coherent = <0x0>;
                        xlnx,clk-50-ddr-otap-dly = <0x0>;
                        xlnx,clk-50-sdr-itap-dly = <0x15>;
                        xlnx,has-emio = <0x0>;
                        clock-frequency = <0xbebba31>;
                        xlnx,tz-nonsecure = <0x1>;
                        xlnx,clk-100-sdr-otap-dly = <0x0>;
                        xlnx,mio-bank = <0x1>;
                        xlnx,ip-name = "psu_sd";
                        xlnx,bus-width = <0x4>;
                        xlnx,card-detect = <0x0>;
                        xlnx,has-wp = <0x1>;
                        xlnx,has-cd = <0x0>;
                        xlnx,slot-type = <0x2>;
                        xlnx,clk-50-sdr-otap-dly = <0x5>;
                        xlnx,clk-50-ddr-itap-dly = <0x0>;
                        xlnx,has-power = <0x0>;
                        xlnx,clk-200-sdr-otap-dly = <0x0>;
                        xlnx,sdio-clk-freq-hz = <0xbebba31>;
                        xlnx,write-protect = <0x1>;
                        xlnx,name = "psu_sd_1";
                        phandle = <0x13>;
                };

                spi0: spi@ff040000 {
                        compatible = "cdns,spi-r1p6";
                        status = "okay";
                        interrupt-parent = <&imux>;
                        interrupts = <0x0 0x13 0x4>;
                        reg = <0x0 0xff040000 0x0 0x1000>;
                        clock-names = "ref_clk", "pclk";
                        #address-cells = <0x1>;
                        #size-cells = <0x0>;
                        power-domains = <&zynqmp_firmware 0x23>;
                        clocks = <&zynqmp_clk 0x3a>,
                         <&zynqmp_clk 0x1f>;
                        xlnx,spi-board-interface = "custom";
                        xlnx,has-ss0 = <0x1>;
                        xlnx,ip-name = "psu_spi";
                        xlnx,has-ss1 = <0x1>;
                        num-cs = <0x3>;
                        xlnx,spi-clk-freq-hz = <0xbebba31>;
                        xlnx,has-ss2 = <0x1>;
                        xlnx,name = "psu_spi_0";
                        phandle = <0x1d>;
                };

                ttc0: timer@ff110000 {
                        compatible = "cdns,ttc";
                        status = "okay";
                        interrupt-parent = <&imux>;
                        interrupts = <0x0 0x24 0x4 0x0 0x25 0x4 0x0 0x26 0x4>;
                        reg = <0x0 0xff110000 0x0 0x1000>;
                        timer-width = <0x20>;
                        power-domains = <&zynqmp_firmware 0x18>;
                        clocks = <&zynqmp_clk 0x1f>;
                        xlnx,ttc-board-interface = "custom";
                        xlnx,ttc-clk2-freq-hz = <0x5f5e100>;
                        xlnx,clock-freq = <0x5f5e100>;
                        xlnx,ip-name = "psu_ttc";
                        xlnx,ttc-clk0-freq-hz = <0x5f5e100>;
                        xlnx,ttc-clk1-freq-hz = <0x5f5e100>;
                        xlnx,name = "psu_ttc_0";
                        phandle = <0x19>;
                };

                ttc1: timer@ff110004 {
                        phandle = <0x117>;
                        xlnx,name = "psu_ttc_1";
                        xlnx,ttc-clk1-freq-hz = <0x5f5e100>;
                        xlnx,ttc-clk0-freq-hz = <0x5f5e100>;
                        xlnx,ip-name = "psu_ttc";
                        xlnx,clock-freq = <0x5f5e100>;
                        xlnx,ttc-clk2-freq-hz = <0x5f5e100>;
                        xlnx,ttc-board-interface = "custom";
                        clocks = <&zynqmp_clk 0x1f>;
                        power-domains = <&zynqmp_firmware 0x18>;
                        timer-width = <0x20>;
                        reg = <0x0 0xff110004 0x0 0xffc>;
                        interrupts = <0x0 0x25 0x4 0x0 0x26 0x4>;
                        interrupt-parent = <&imux>;
                        status = "okay";
                        compatible = "cdns,ttc";
                        lop-dynamic-ttc-node = <0x1>;
                };

                ttc2: timer@ff110008 {
                        phandle = <0x118>;
                        xlnx,name = "psu_ttc_2";
                        xlnx,ttc-clk1-freq-hz = <0x5f5e100>;
                        xlnx,ttc-clk0-freq-hz = <0x5f5e100>;
                        xlnx,ip-name = "psu_ttc";
                        xlnx,clock-freq = <0x5f5e100>;
                        xlnx,ttc-clk2-freq-hz = <0x5f5e100>;
                        xlnx,ttc-board-interface = "custom";
                        clocks = <&zynqmp_clk 0x1f>;
                        power-domains = <&zynqmp_firmware 0x18>;
                        timer-width = <0x20>;
                        reg = <0x0 0xff110008 0x0 0xff8>;
                        interrupts = <0x0 0x26 0x4>;
                        interrupt-parent = <&imux>;
                        status = "okay";
                        compatible = "cdns,ttc";
                        lop-dynamic-ttc-node = <0x1>;
                };

                ttc3: timer@ff120000 {
                        compatible = "cdns,ttc";
                        status = "okay";
                        interrupt-parent = <&imux>;
                        interrupts = <0x0 0x27 0x4 0x0 0x28 0x4 0x0 0x29 0x4>;
                        reg = <0x0 0xff120000 0x0 0x1000>;
                        timer-width = <0x20>;
                        power-domains = <&zynqmp_firmware 0x19>;
                        clocks = <&zynqmp_clk 0x1f>;
                        xlnx,ttc-board-interface = "custom";
                        xlnx,ttc-clk2-freq-hz = <0x5f5e100>;
                        xlnx,clock-freq = <0x5f5e100>;
                        xlnx,ip-name = "psu_ttc";
                        xlnx,ttc-clk0-freq-hz = <0x5f5e100>;
                        xlnx,ttc-clk1-freq-hz = <0x5f5e100>;
                        xlnx,name = "psu_ttc_3";
                        phandle = <0x18>;
                };

                ttc4: timer@ff120004 {
                        phandle = <0x119>;
                        xlnx,name = "psu_ttc_4";
                        xlnx,ttc-clk1-freq-hz = <0x5f5e100>;
                        xlnx,ttc-clk0-freq-hz = <0x5f5e100>;
                        xlnx,ip-name = "psu_ttc";
                        xlnx,clock-freq = <0x5f5e100>;
                        xlnx,ttc-clk2-freq-hz = <0x5f5e100>;
                        xlnx,ttc-board-interface = "custom";
                        clocks = <&zynqmp_clk 0x1f>;
                        power-domains = <&zynqmp_firmware 0x19>;
                        timer-width = <0x20>;
                        reg = <0x0 0xff120004 0x0 0xffc>;
                        interrupts = <0x0 0x28 0x4 0x0 0x29 0x4>;
                        interrupt-parent = <&imux>;
                        status = "okay";
                        compatible = "cdns,ttc";
                        lop-dynamic-ttc-node = <0x1>;
                };

                ttc5: timer@ff120008 {
                        phandle = <0x11a>;
                        xlnx,name = "psu_ttc_5";
                        xlnx,ttc-clk1-freq-hz = <0x5f5e100>;
                        xlnx,ttc-clk0-freq-hz = <0x5f5e100>;
                        xlnx,ip-name = "psu_ttc";
                        xlnx,clock-freq = <0x5f5e100>;
                        xlnx,ttc-clk2-freq-hz = <0x5f5e100>;
                        xlnx,ttc-board-interface = "custom";
                        clocks = <&zynqmp_clk 0x1f>;
                        power-domains = <&zynqmp_firmware 0x19>;
                        timer-width = <0x20>;
                        reg = <0x0 0xff120008 0x0 0xff8>;
                        interrupts = <0x0 0x29 0x4>;
                        interrupt-parent = <&imux>;
                        status = "okay";
                        compatible = "cdns,ttc";
                        lop-dynamic-ttc-node = <0x1>;
                };

                ttc6: timer@ff130000 {
                        compatible = "cdns,ttc";
                        status = "okay";
                        interrupt-parent = <&imux>;
                        interrupts = <0x0 0x2a 0x4 0x0 0x2b 0x4 0x0 0x2c 0x4>;
                        reg = <0x0 0xff130000 0x0 0x1000>;
                        timer-width = <0x20>;
                        power-domains = <&zynqmp_firmware 0x1a>;
                        clocks = <&zynqmp_clk 0x1f>;
                        xlnx,ttc-board-interface = "custom";
                        xlnx,ttc-clk2-freq-hz = <0x5f5e100>;
                        xlnx,clock-freq = <0x5f5e100>;
                        xlnx,ip-name = "psu_ttc";
                        xlnx,ttc-clk0-freq-hz = <0x5f5e100>;
                        xlnx,ttc-clk1-freq-hz = <0x5f5e100>;
                        xlnx,name = "psu_ttc_6";
                        phandle = <0x17>;
                };

                ttc7: timer@ff130004 {
                        phandle = <0x11b>;
                        xlnx,name = "psu_ttc_7";
                        xlnx,ttc-clk1-freq-hz = <0x5f5e100>;
                        xlnx,ttc-clk0-freq-hz = <0x5f5e100>;
                        xlnx,ip-name = "psu_ttc";
                        xlnx,clock-freq = <0x5f5e100>;
                        xlnx,ttc-clk2-freq-hz = <0x5f5e100>;
                        xlnx,ttc-board-interface = "custom";
                        clocks = <&zynqmp_clk 0x1f>;
                        power-domains = <&zynqmp_firmware 0x1a>;
                        timer-width = <0x20>;
                        reg = <0x0 0xff130004 0x0 0xffc>;
                        interrupts = <0x0 0x2b 0x4 0x0 0x2c 0x4>;
                        interrupt-parent = <&imux>;
                        status = "okay";
                        compatible = "cdns,ttc";
                        lop-dynamic-ttc-node = <0x1>;
                };

                ttc8: timer@ff130008 {
                        phandle = <0x11c>;
                        xlnx,name = "psu_ttc_8";
                        xlnx,ttc-clk1-freq-hz = <0x5f5e100>;
                        xlnx,ttc-clk0-freq-hz = <0x5f5e100>;
                        xlnx,ip-name = "psu_ttc";
                        xlnx,clock-freq = <0x5f5e100>;
                        xlnx,ttc-clk2-freq-hz = <0x5f5e100>;
                        xlnx,ttc-board-interface = "custom";
                        clocks = <&zynqmp_clk 0x1f>;
                        power-domains = <&zynqmp_firmware 0x1a>;
                        timer-width = <0x20>;
                        reg = <0x0 0xff130008 0x0 0xff8>;
                        interrupts = <0x0 0x2c 0x4>;
                        interrupt-parent = <&imux>;
                        status = "okay";
                        compatible = "cdns,ttc";
                        lop-dynamic-ttc-node = <0x1>;
                };

                ttc9: timer@ff140000 {
                        compatible = "cdns,ttc";
                        status = "okay";
                        interrupt-parent = <&imux>;
                        interrupts = <0x0 0x2d 0x4 0x0 0x2e 0x4 0x0 0x2f 0x4>;
                        reg = <0x0 0xff140000 0x0 0x1000>;
                        timer-width = <0x20>;
                        power-domains = <&zynqmp_firmware 0x1b>;
                        clocks = <&zynqmp_clk 0x1f>;
                        xlnx,ttc-board-interface = "custom";
                        xlnx,ttc-clk2-freq-hz = <0x5f5e100>;
                        xlnx,clock-freq = <0x5f5e100>;
                        xlnx,ip-name = "psu_ttc";
                        xlnx,ttc-clk0-freq-hz = <0x5f5e100>;
                        xlnx,ttc-clk1-freq-hz = <0x5f5e100>;
                        xlnx,name = "psu_ttc_9";
                        phandle = <0x16>;
                };

                ttc10: timer@ff140004 {
                        phandle = <0x11d>;
                        xlnx,name = "psu_ttc_10";
                        xlnx,ttc-clk1-freq-hz = <0x5f5e100>;
                        xlnx,ttc-clk0-freq-hz = <0x5f5e100>;
                        xlnx,ip-name = "psu_ttc";
                        xlnx,clock-freq = <0x5f5e100>;
                        xlnx,ttc-clk2-freq-hz = <0x5f5e100>;
                        xlnx,ttc-board-interface = "custom";
                        clocks = <&zynqmp_clk 0x1f>;
                        power-domains = <&zynqmp_firmware 0x1b>;
                        timer-width = <0x20>;
                        reg = <0x0 0xff140004 0x0 0xffc>;
                        interrupts = <0x0 0x2e 0x4 0x0 0x2f 0x4>;
                        interrupt-parent = <&imux>;
                        status = "okay";
                        compatible = "cdns,ttc";
                        lop-dynamic-ttc-node = <0x1>;
                };

                ttc11: timer@ff140008 {
                        phandle = <0x11e>;
                        xlnx,name = "psu_ttc_11";
                        xlnx,ttc-clk1-freq-hz = <0x5f5e100>;
                        xlnx,ttc-clk0-freq-hz = <0x5f5e100>;
                        xlnx,ip-name = "psu_ttc";
                        xlnx,clock-freq = <0x5f5e100>;
                        xlnx,ttc-clk2-freq-hz = <0x5f5e100>;
                        xlnx,ttc-board-interface = "custom";
                        clocks = <&zynqmp_clk 0x1f>;
                        power-domains = <&zynqmp_firmware 0x1b>;
                        timer-width = <0x20>;
                        reg = <0x0 0xff140008 0x0 0xff8>;
                        interrupts = <0x0 0x2f 0x4>;
                        interrupt-parent = <&imux>;
                        status = "okay";
                        compatible = "cdns,ttc";
                        lop-dynamic-ttc-node = <0x1>;
                };

                uart0: serial@ff000000 {
                        bootph-all;
                        compatible = "xlnx,zynqmp-uart", "cdns,uart-r1p12";
                        status = "okay";
                        interrupt-parent = <&imux>;
                        interrupts = <0x0 0x15 0x4>;
                        reg = <0x0 0xff000000 0x0 0x1000>;
                        clock-names = "uart_clk", "pclk";
                        power-domains = <&zynqmp_firmware 0x21>;
                        clocks = <&zynqmp_clk 0x38>,
                         <&zynqmp_clk 0x1f>;
                        assigned-clocks = <&zynqmp_clk 0x38>;
                        xlnx,clock-freq = <0x5f5dd19>;
                        u-boot,dm-pre-reloc;
                        xlnx,uart-board-interface = "custom";
                        xlnx,has-modem = <0x0>;
                        xlnx,ip-name = "psu_uart";
                        xlnx,baudrate = <0x1c200>;
                        cts-override;
                        port-number = <0x0>;
                        xlnx,uart-clk-freq-hz = <0x5f5dd19>;
                        xlnx,name = "psu_uart_0";
                        phandle = <0x20>;
                };

                uart1: serial@ff010000 {
                        bootph-all;
                        compatible = "xlnx,zynqmp-uart", "cdns,uart-r1p12";
                        status = "okay";
                        interrupt-parent = <&imux>;
                        interrupts = <0x0 0x16 0x4>;
                        reg = <0x0 0xff010000 0x0 0x1000>;
                        clock-names = "uart_clk", "pclk";
                        power-domains = <&zynqmp_firmware 0x22>;
                        clocks = <&zynqmp_clk 0x39>,
                         <&zynqmp_clk 0x1f>;
                        assigned-clocks = <&zynqmp_clk 0x39>;
                        xlnx,clock-freq = <0x5f5dd19>;
                        u-boot,dm-pre-reloc;
                        xlnx,uart-board-interface = "custom";
                        xlnx,has-modem = <0x0>;
                        xlnx,ip-name = "psu_uart";
                        xlnx,baudrate = <0x1c200>;
                        cts-override;
                        port-number = <0x0>;
                        xlnx,uart-clk-freq-hz = <0x5f5dd19>;
                        xlnx,name = "psu_uart_1";
                        phandle = <0x1f>;
                };

                usb0: usb@ff9d0000 {
                        #address-cells = <0x2>;
                        #size-cells = <0x2>;
                        status = "okay";
                        compatible = "xlnx,zynqmp-dwc3";
                        reg = <0x0 0xff9d0000 0x0 0x100>;
                        clock-names = "bus_clk", "ref_clk";
                        power-domains = <&zynqmp_firmware 0x16>;
                        reset-names = "usb_crst", "usb_hibrst", "usb_apbrst";
                        reset-gpios = <&modepin_gpio 0x1 0x1>;
                        ranges;
                        clocks = <&zynqmp_clk 0x20>,
                         <&zynqmp_clk 0x22>;
                        assigned-clocks = <&zynqmp_clk 0x20>,
                         <&zynqmp_clk 0x22>;
                        xlnx,is-cache-coherent = <0x0>;
                        xlnx,usb-polarity = <0x0>;
                        xlnx,ip-name = "psu_usb";
                        xlnx,usb-reset-mode = <0x0>;
                        xlnx,usb-board-interface = "custom";
                        xlnx,tz-nonsecure = <0x1>;
                        xlnx,name = "psu_usb_0";
                        phandle = <0x21>;
                };

                lpd_watchdog: watchdog@ff150000 {
                        compatible = "cdns,wdt-r1p2";
                        status = "okay";
                        interrupt-parent = <&imux>;
                        interrupts = <0x0 0x34 0x1>;
                        reg = <0x0 0xff150000 0x0 0x1000>;
                        timeout-sec = <0xa>;
                        clocks = <&zynqmp_clk 0x70>;
                        xlnx,ip-name = "psu_wdt";
                        xlnx,wdt-clk-freq-hz = <0x5f5dd19>;
                        xlnx,swdt-board-interface = "custom";
                        xlnx,name = "psu_wdt_0";
                        phandle = <0x15>;
                };

                xilinx_ams: ams@ffa50000 {
                        compatible = "xlnx,zynqmp-ams";
                        interrupt-parent = <&imux>;
                        interrupts = <0x0 0x38 0x4>;
                        reg = <0x0 0xffa50000 0x0 0x800>;
                        #address-cells = <0x1>;
                        #size-cells = <0x1>;
                        #io-channel-cells = <0x1>;
                        ranges = <0x0 0x0 0xffa50800 0x800>;
                        clocks = <&zynqmp_clk 0x46>;
                        status = "okay";
                        xlnx,clock-freq = <0x31>;
                        xlnx,ip-name = "psu_ams";
                        xlnx,name = "psu_ams";
                        phandle = <0x37>;
                };

                csudma_0: dma@ffc80000 {
                        status = "okay";
                        compatible = "xlnx,zynqmp-csudma-1.0";
                        interrupt-parent = <&imux>;
                        interrupts = <0x0 0x56 0x4>;
                        reg = <0x0 0xffc80000 0x0 0x40000>;
                        xlnx,ip-name = "psu_csudma";
                        xlnx,dma-type = <0x0>;
                        xlnx,name = "psu_csudma";
                        phandle = <0x2c>;
                };

                psu_r5_tcm_ram_global: psu_r5_tcm_ram@ffe00000 {
                        compatible = "xlnx,psu-r5-tcm-ram-1.0", "mmio-sram";
                        status = "okay";
                        power-domains = <&zynqmp_firmware 0xf>;
                        xlnx,ip-name = "psu_r5_tcm_ram";
                        reg = <0x0 0xffe00000 0x0 0x40000>;
                        xlnx,name = "psu_r5_tcm_ram_global";
                        phandle = <0x68>;
                };

                psu_r5_tcm_ram_0: psu_r5_tcm_ram@0 {
                        compatible = "xlnx,psu-r5-tcm-ram-1.0";
                        status = "okay";
                        power-domains = <&zynqmp_firmware 0xf>;
                        xlnx,ip-name = "psu_r5_tcm_ram";
                        reg = <0x0 0x0 0x0 0x40000>;
                        xlnx,name = "psu_r5_tcm_ram_0";
                        phandle = <0x79>;
                };

                psu_r5_1_btcm: psu_r5_1_btcm@20000 {
                        xlnx,power-domain = <0x10>;
                        compatible = "xlnx,psu-r5-1-btcm-1.0";
                        status = "okay";
                        power-domains = <&zynqmp_firmware 0x12>;
                        xlnx,ip-name = "psu_r5_1_btcm";
                        xlnx,bank-size = <0x10000>;
                        reg = <0x0 0x20000 0x0 0x10000>;
                        xlnx,name = "psu_r5_1_btcm";
                        phandle = <0x7e>;
                };

                psu_r5_1_btcm_global: psu_r5_1_btcm_global@ffeb0000 {
                        compatible = "xlnx,psu-r5-1-btcm-global-1.0", "mmio-sram";
                        status = "okay";
                        power-domains = <&zynqmp_firmware 0x12>;
                        xlnx,ip-name = "psu_r5_1_btcm_global";
                        reg = <0x0 0xffeb0000 0x0 0x10000>;
                        xlnx,name = "psu_r5_1_btcm_global";
                        phandle = <0x22>;
                };

                psu_r5_1_atcm: psu_r5_1_atcm@0 {
                        xlnx,power-domain = <0xf>;
                        compatible = "xlnx,psu-r5-1-atcm-1.0";
                        status = "okay";
                        power-domains = <&zynqmp_firmware 0x11>;
                        xlnx,ip-name = "psu_r5_1_atcm";
                        xlnx,bank-size = <0x10000>;
                        reg = <0x0 0x0 0x0 0x10000>;
                        xlnx,name = "psu_r5_1_atcm";
                        phandle = <0x7d>;
                };

                psu_r5_1_atcm_global: psu_r5_1_atcm_global@ffe90000 {
                        compatible = "xlnx,psu-r5-1-atcm-global-1.0", "mmio-sram";
                        status = "okay";
                        power-domains = <&zynqmp_firmware 0x11>;
                        xlnx,ip-name = "psu_r5_1_atcm_global";
                        reg = <0x0 0xffe90000 0x0 0x10000>;
                        xlnx,name = "psu_r5_1_atcm_global";
                        phandle = <0x24>;
                };

                psu_r5_0_btcm_lockstep: psu_r5_0_btcm_lockstep@ffe30000 {
                        compatible = "xlnx,psu-r5-0-btcm-lockstep-1.0", "mmio-sram";
                        status = "okay";
                        power-domains = <&zynqmp_firmware 0x10>;
                        xlnx,ip-name = "psu_r5_0_btcm_lockstep";
                        xlnx,is-hierarchy;
                        reg = <0x0 0xffe30000 0x0 0x10000>;
                        xlnx,name = "psu_r5_0_btcm_lockstep";
                        phandle = <0x10c>;
                };

                psu_r5_0_btcm: psu_r5_0_btcm@20000 {
                        xlnx,power-domain = <0x12>;
                        compatible = "xlnx,psu-r5-0-btcm-1.0";
                        status = "okay";
                        power-domains = <&zynqmp_firmware 0x10>;
                        xlnx,ip-name = "psu_r5_0_btcm";
                        xlnx,bank-size = <0x10000>;
                        reg = <0x0 0x20000 0x0 0x10000>;
                        xlnx,name = "psu_r5_0_btcm";
                        phandle = <0x78>;
                };

                psu_r5_0_btcm_global: psu_r5_0_btcm_global@ffe20000 {
                        compatible = "xlnx,psu-r5-0-btcm-global-1.0", "mmio-sram";
                        status = "okay";
                        power-domains = <&zynqmp_firmware 0x10>;
                        xlnx,ip-name = "psu_r5_0_btcm_global";
                        reg = <0x0 0xffe20000 0x0 0x10000>;
                        xlnx,name = "psu_r5_0_btcm_global";
                        phandle = <0x25>;
                };

                psu_r5_0_atcm_lockstep: psu_r5_0_atcm_lockstep@ffe10000 {
                        compatible = "xlnx,psu-r5-0-atcm-lockstep-1.0", "mmio-sram";
                        status = "okay";
                        power-domains = <&zynqmp_firmware 0xf>;
                        xlnx,ip-name = "psu_r5_0_atcm_lockstep";
                        xlnx,is-hierarchy;
                        reg = <0x0 0xffe10000 0x0 0x10000>;
                        xlnx,name = "psu_r5_0_atcm_lockstep";
                        phandle = <0x10d>;
                };

                psu_r5_0_atcm: psu_r5_0_atcm@0 {
                        xlnx,power-domain = <0x11>;
                        compatible = "xlnx,psu-r5-0-atcm-1.0";
                        status = "okay";
                        power-domains = <&zynqmp_firmware 0xf>;
                        xlnx,ip-name = "psu_r5_0_atcm";
                        xlnx,bank-size = <0x10000>;
                        reg = <0x0 0x0 0x0 0x10000>;
                        xlnx,name = "psu_r5_0_atcm";
                        phandle = <0x77>;
                };

                psu_r5_0_atcm_global: psu_r5_0_atcm_global@ffe00000 {
                        compatible = "xlnx,psu-r5-0-atcm-global-1.0", "mmio-sram";
                        status = "okay";
                        power-domains = <&zynqmp_firmware 0xf>;
                        xlnx,ip-name = "psu_r5_0_atcm_global";
                        reg = <0x0 0xffe00000 0x0 0x10000>;
                        xlnx,name = "psu_r5_0_atcm_global";
                        phandle = <0x26>;
                };

                psu_pmu_global_0: psu_pmu_global_0@ffd80000 {
                        compatible = "xlnx,psu-pmu-global-0-1.0";
                        status = "okay";
                        xlnx,ip-name = "psu_pmu_global_0";
                        reg = <0x0 0xffd80000 0x0 0x40000>;
                        xlnx,name = "psu_pmu_global_0";
                        phandle = <0x27>;
                };

                psu_mbistjtag: psu_mbistjtag@ffcf0000 {
                        compatible = "xlnx,psu-mbistjtag-1.0";
                        status = "okay";
                        xlnx,ip-name = "psu_mbistjtag";
                        reg = <0x0 0xffcf0000 0x0 0x10000>;
                        xlnx,name = "psu_mbistjtag";
                        phandle = <0x28>;
                };

                psu_rsa: psu_rsa@ffce0000 {
                        compatible = "xlnx,psu-rsa-1.0";
                        status = "okay";
                        xlnx,ip-name = "psu_rsa";
                        reg = <0x0 0xffce0000 0x0 0x10000>;
                        xlnx,name = "psu_rsa";
                        phandle = <0x29>;
                };

                psu_efuse: psu_efuse@ffcc0000 {
                        compatible = "xlnx,psu-efuse-1.0";
                        status = "okay";
                        xlnx,ip-name = "psu_efuse";
                        reg = <0x0 0xffcc0000 0x0 0x10000>;
                        xlnx,name = "psu_efuse";
                        phandle = <0x2a>;
                };

                psu_csu_0: psu_csu@ffca0000 {
                        xlnx,csu-board-interface = "custom";
                        compatible = "xlnx,psu-csu-1.0";
                        status = "okay";
                        xlnx,can-clk-freq-hz = <0xaba9500>;
                        xlnx,ip-name = "psu_csu";
                        reg = <0x0 0xffca0000 0x0 0x10000>;
                        xlnx,name = "psu_csu_0";
                        phandle = <0x2b>;
                };

                psu_ocm_xmpu_cfg: psu_ocm_xmpu_cfg@ffa70000 {
                        compatible = "xlnx,psu-ocm-xmpu-cfg-1.0";
                        status = "okay";
                        xlnx,ip-name = "psu_ocm_xmpu_cfg";
                        reg = <0x0 0xffa70000 0x0 0x10000>;
                        xlnx,name = "psu_ocm_xmpu_cfg";
                        phandle = <0x35>;
                };

                psu_lpd_xppu_sink: psu_lpd_xppu_sink@ff9c0000 {
                        compatible = "xlnx,psu-lpd-xppu-sink-1.0";
                        status = "okay";
                        xlnx,ip-name = "psu_lpd_xppu_sink";
                        reg = <0x0 0xff9c0000 0x0 0x10000>;
                        xlnx,name = "psu_lpd_xppu_sink";
                        phandle = <0x3a>;
                };

                psu_afi_6: psu_afi@ff9b0000 {
                        compatible = "xlnx,psu-afi-1.0";
                        status = "okay";
                        xlnx,ip-name = "psu_afi";
                        reg = <0x0 0xff9b0000 0x0 0x10000>;
                        xlnx,name = "psu_afi_6";
                        phandle = <0x3b>;
                };

                psu_rpu: psu_rpu@ff9a0000 {
                        xlnx,is-cache-coherent = <0x0>;
                        compatible = "xlnx,psu-rpu-1.0";
                        status = "okay";
                        xlnx,ip-name = "psu_rpu";
                        reg = <0x0 0xff9a0000 0x0 0x10000>;
                        xlnx,name = "psu_rpu";
                        phandle = <0x3c>;
                };

                psu_crl_apb: psu_crl_apb@ff5e0000 {
                        compatible = "xlnx,psu-crl-apb-1.0";
                        status = "okay";
                        xlnx,ip-name = "psu_crl_apb";
                        reg = <0x0 0xff5e0000 0x0 0x280000 0x0 0xff5e0000 0x0 0x220000 0x0 0xff800000 0x0 0x60000>;
                        xlnx,name = "psu_crl_apb";
                        phandle = <0xb>;
                };

                psu_lpd_slcr_secure: psu_lpd_slcr_secure@ff4b0000 {
                        compatible = "xlnx,psu-lpd-slcr-secure-1.0";
                        status = "okay";
                        xlnx,ip-name = "psu_lpd_slcr_secure";
                        reg = <0x0 0xff4b0000 0x0 0x30000>;
                        xlnx,name = "psu_lpd_slcr_secure";
                        phandle = <0xc>;
                };

                psu_lpd_slcr: psu_lpd_slcr@ff410000 {
                        compatible = "xlnx,psu-lpd-slcr-1.0";
                        status = "okay";
                        xlnx,ip-name = "psu_lpd_slcr";
                        reg = <0x0 0xff410000 0x0 0xa0000>;
                        xlnx,name = "psu_lpd_slcr";
                        phandle = <0xd>;
                };

                psu_ctrl_ipi: PERIPHERAL@ff380000 {
                        compatible = "xlnx,PERIPHERAL-1.0";
                        reg = <0x0 0xff380000 0x0 0x80000>;
                        phandle = <0xe>;
                };

                psu_message_buffers: PERIPHERAL@ff990000 {
                        compatible = "xlnx,PERIPHERAL-1.0";
                        reg = <0x0 0xff990000 0x0 0x10000>;
                        phandle = <0x3e>;
                };

                psu_iou_scntrs: psu_iou_scntrs@ff260000 {
                        compatible = "xlnx,psu-iou-scntrs-1.0";
                        status = "okay";
                        xlnx,ip-name = "psu_iou_scntrs";
                        reg = <0x0 0xff260000 0x0 0x10000>;
                        xlnx,name = "psu_iou_scntrs";
                        phandle = <0xf>;
                };

                psu_iou_scntr: psu_iou_scntr@ff250000 {
                        compatible = "xlnx,psu-iou-scntr-1.0";
                        status = "okay";
                        xlnx,ip-name = "psu_iou_scntr";
                        reg = <0x0 0xff250000 0x0 0x10000>;
                        xlnx,name = "psu_iou_scntr";
                        phandle = <0x10>;
                };

                psu_iousecure_slcr: psu_iousecure_slcr@ff240000 {
                        compatible = "xlnx,psu-iousecure-slcr-1.0";
                        status = "okay";
                        xlnx,ip-name = "psu_iousecure_slcr";
                        reg = <0x0 0xff240000 0x0 0x10000>;
                        xlnx,name = "psu_iousecure_slcr";
                        phandle = <0x11>;
                };

                psu_iouslcr_0: psu_iouslcr@ff180000 {
                        compatible = "xlnx,psu-iouslcr-1.0";
                        status = "okay";
                        xlnx,ip-name = "psu_iouslcr";
                        reg = <0x0 0xff180000 0x0 0xc0000>;
                        xlnx,name = "psu_iouslcr_0";
                        phandle = <0x12>;
                };

                psu_qspi_linear_0: psu_qspi_linear@c0000000 {
                        reg = <0x0 0xc0000000 0x0 0x20000000 0x0 0xc0000000 0x0 0x10000000 0x0 0xd0000000 0x0 0x10000000>;
                        phandle = <0x110>;
                };
        };

        amba_xppu: indirect-bus@1 {
                compatible = "indirect-bus";
                #address-cells = <0x2>;
                #size-cells = <0x2>;
                phandle = <0x111>;

                lpd_xppu: xppu@ff980000 {
                        compatible = "xlnx,xppu";
                        #firewall-cells = <0x0>;
                        reg = <0x0 0xff980000 0x0 0x1000>;
                        status = "okay";
                        xlnx,ip-name = "psu_lpd_xppu";
                        xlnx,name = "psu_lpd_xppu";
                        phandle = <0x3d>;
                };
        };

        binman: binman {
                phandle = <0x112>;
        };

        pss_ref_clk: pss-ref-clk {
                bootph-all;
                compatible = "fixed-clock";
                #clock-cells = <0x0>;
                clock-frequency = <0x1fca055>;
                clock-output-names = "pss_ref_clk";
                phandle = <0x8c>;
        };

        video_clk: video-clk {
                bootph-all;
                compatible = "fixed-clock";
                #clock-cells = <0x0>;
                clock-frequency = <0x19bfcc0>;
                clock-output-names = "video_clk";
                phandle = <0x8d>;
        };

        pss_alt_ref_clk: pss-alt-ref-clk {
                bootph-all;
                compatible = "fixed-clock";
                #clock-cells = <0x0>;
                clock-frequency = <0x0>;
                clock-output-names = "pss_alt_ref_clk";
                phandle = <0x8e>;
        };

        gt_crx_ref_clk: gt-crx-ref-clk {
                bootph-all;
                compatible = "fixed-clock";
                #clock-cells = <0x0>;
                clock-frequency = <0x66ff300>;
                clock-output-names = "gt_crx_ref_clk";
                phandle = <0x90>;
        };

        aux_ref_clk: aux-ref-clk {
                bootph-all;
                compatible = "fixed-clock";
                #clock-cells = <0x0>;
                clock-frequency = <0x19bfcc0>;
                clock-output-names = "aux_ref_clk";
                phandle = <0x8f>;
        };

        cpus_microblaze_riscv_0: cpus_microblaze_riscv@0 {
                #cpu-mask-cells = <0x1>;
                compatible = "cpus,cluster";
                #address-cells = <0x1>;
                #size-cells = <0x0>;
                address-map = <0x90000000 &microblaze_riscv_0_local_memory_dlmb_bram_if_cntlr_memory 0x90000000 0x40000>,
                 <0x90000000 &microblaze_riscv_0_local_memory_dlmb_bram_if_cntlr 0x90000000 0x40000>,
                 <0x90080000 &microblaze_riscv_0_local_memory_ilmb_bram_if_cntlr_memory 0x90080000 0x40000>,
                 <0x90080000 &microblaze_riscv_0_local_memory_ilmb_bram_if_cntlr 0x90080000 0x40000>,
                 <0xfffc0000 &psu_ocm_ram_0_memory 0xfffc0000 0x40000>,
                 <0x0 &psu_ddr_0_memory 0x0 0x40000000>,
                 <0x60000000 &psu_ddr_0_memory 0x60000000 0x1ff00000>,
                 <0x80000000 &axi_gpio_1 0x80000000 0x10000>,
                 <0x80010000 &axi_intc_0 0x80010000 0x10000>,
                 <0x80020000 &pl_ps_intr 0x80020000 0x10000>,
                 <0xc0000000 &psu_qspi_linear_0_memory 0xc0000000 0x10000000>,
                 <0xff5e0000 &psu_crl_apb 0xff5e0000 0x220000>,
                 <0xff4b0000 &psu_lpd_slcr_secure 0xff4b0000 0x30000>,
                 <0xff410000 &psu_lpd_slcr 0xff410000 0xa0000>,
                 <0xff380000 &psu_ctrl_ipi 0xff380000 0x80000>,
                 <0xff260000 &psu_iou_scntrs 0xff260000 0x10000>,
                 <0xff250000 &psu_iou_scntr 0xff250000 0x10000>,
                 <0xff240000 &psu_iousecure_slcr 0xff240000 0x10000>,
                 <0xff180000 &psu_iouslcr_0 0xff180000 0xc0000>,
                 <0xff170000 &sdhci1 0xff170000 0x10000>,
                 <0xff160000 &sdhci0 0xff160000 0x10000>,
                 <0xff150000 &lpd_watchdog 0xff150000 0x10000>,
                 <0xff140000 &ttc9 0xff140000 0x10000>,
                 <0xff130000 &ttc6 0xff130000 0x10000>,
                 <0xff120000 &ttc3 0xff120000 0x10000>,
                 <0xff110000 &ttc0 0xff110000 0x10000>,
                 <0xff0f0000 &qspi 0xff0f0000 0x10000>,
                 <0xff0e0000 &gem3 0xff0e0000 0x10000>,
                 <0xff0a0000 &gpio 0xff0a0000 0x10000>,
                 <0xff040000 &spi0 0xff040000 0x10000>,
                 <0xff030000 &i2c1 0xff030000 0x10000>,
                 <0xff010000 &uart1 0xff010000 0x10000>,
                 <0xff000000 &uart0 0xff000000 0x10000>,
                 <0xff9d0000 &usb0 0xff9d0000 0x10000>,
                 <0xffeb0000 &psu_r5_1_btcm_global 0xffeb0000 0x10000>,
                 <0xff960000 &ocm 0xff960000 0x10000>,
                 <0xffe90000 &psu_r5_1_atcm_global 0xffe90000 0x10000>,
                 <0xffe20000 &psu_r5_0_btcm_global 0xffe20000 0x10000>,
                 <0xffe00000 &psu_r5_0_atcm_global 0xffe00000 0x10000>,
                 <0xffd80000 &psu_pmu_global_0 0xffd80000 0x40000>,
                 <0xffcf0000 &psu_mbistjtag 0xffcf0000 0x10000>,
                 <0xffce0000 &psu_rsa 0xffce0000 0x10000>,
                 <0xffcc0000 &psu_efuse 0xffcc0000 0x10000>,
                 <0xffca0000 &psu_csu_0 0xffca0000 0x10000>,
                 <0xffc80000 &csudma_0 0xffc80000 0x20000>,
                 <0xffaf0000 &lpd_dma_chan8 0xffaf0000 0x10000>,
                 <0xffae0000 &lpd_dma_chan7 0xffae0000 0x10000>,
                 <0xffad0000 &lpd_dma_chan6 0xffad0000 0x10000>,
                 <0xffac0000 &lpd_dma_chan5 0xffac0000 0x10000>,
                 <0xffab0000 &lpd_dma_chan4 0xffab0000 0x10000>,
                 <0xffaa0000 &lpd_dma_chan3 0xffaa0000 0x10000>,
                 <0xffa90000 &lpd_dma_chan2 0xffa90000 0x10000>,
                 <0xffa80000 &lpd_dma_chan1 0xffa80000 0x10000>,
                 <0xffa70000 &psu_ocm_xmpu_cfg 0xffa70000 0x10000>,
                 <0xffa60000 &rtc 0xffa60000 0x10000>,
                 <0xffa50000 &xilinx_ams 0xffa50000 0x10000>,
                 <0xffa10000 &perf_monitor_lpd 0xffa10000 0x10000>,
                 <0xffa00000 &perf_monitor_ocm 0xffa00000 0x10000>,
                 <0xff9c0000 &psu_lpd_xppu_sink 0xff9c0000 0x10000>,
                 <0xff9b0000 &psu_afi_6 0xff9b0000 0x10000>,
                 <0xff9a0000 &psu_rpu 0xff9a0000 0x10000>,
                 <0xff980000 &lpd_xppu 0xff980000 0x10000>,
                 <0xff990000 &psu_message_buffers 0xff990000 0x10000>;
                #ranges-address-cells = <0x1>;
                #ranges-size-cells = <0x1>;
                phandle = <0x113>;

                microblaze_riscv_0: cpu@0 {
                        xlnx,d-axi = <0x1>;
                        xlnx,pmp-entries = <0x0>;
                        xlnx,temporal-depth = <0x0>;
                        xlnx,dcache-force-tag-lutram = <0x0>;
                        reg = <0x0>;
                        xlnx,interrupt-is-edge = <0x0>;
                        xlnx,use-mmu = <0x0>;
                        xlnx,dc-axi-mon = <0x0>;
                        xlnx,debug-trace-async-reset = <0x0>;
                        xlnx,part = "xczu3eg-sfvc784-1-e";
                        xlnx,use-config-reset = <0x0>;
                        xlnx,family = "zynquplus";
                        xlnx,use-sleep = <0x0>;
                        xlnx,enable-discrete-ports = <0x0>;
                        xlnx,d-lmb = <0x1>;
                        xlnx,debug-interface = <0x0>;
                        xlnx,use-ext-brk = <0x0>;
                        xlnx,debug-enabled = <0x1>;
                        xlnx,daddr-size = <0x20>;
                        xlnx,use-extended-fsl-instr = <0x0>;
                        xlnx,branch-target-cache-size = <0x0>;
                        bus-handle = <0xa0>;
                        xlnx,pmp-addr0 = <0x0>;
                        xlnx,pmp-addr1 = <0x0>;
                        xlnx,pmp-addr2 = <0x0>;
                        xlnx,pmp-addr3 = <0x0>;
                        xlnx,pmp-addr4 = <0x0>;
                        xlnx,edk-special = "microblaze_riscv";
                        xlnx,pmp-addr5 = <0x0>;
                        xlnx,use-dcache = <0x0>;
                        xlnx,use-muldiv = <0x0>;
                        xlnx,pmp-addr6 = <0x0>;
                        xlnx,use-axi-dp-ext-addr = <0x0>;
                        xlnx,pmp-addr7 = <0x0>;
                        xlnx,pmp-addr8 = <0x0>;
                        xlnx,pmp-addr9 = <0x0>;
                        xlnx,i-axi = <0x1>;
                        xlnx,icache-streams = <0x0>;
                        xlnx,num-sync-ff-dbg-clk = <0x1>;
                        xlnx,icache-byte-size = <0x4000>;
                        xlnx,pmp-addr10 = <0x0>;
                        d-cache-size = <0x4000>;
                        xlnx,pmp-addr11 = <0x0>;
                        xlnx,pmp-addr12 = <0x0>;
                        xlnx,pmp-addr13 = <0x0>;
                        xlnx,pmp-addr14 = <0x0>;
                        xlnx,pmp-addr15 = <0x0>;
                        xlnx,avoid-primitives = <0x0>;
                        xlnx,pmp-addr16 = <0x0>;
                        xlnx,pmp-addr17 = <0x0>;
                        xlnx,pmp-addr18 = <0x0>;
                        xlnx,pdaddr-size = <0x20>;
                        xlnx,pmp-addr19 = <0x0>;
                        xlnx,pmp-addr20 = <0x0>;
                        xlnx,pmp-addr21 = <0x0>;
                        xlnx,i-lmb = <0x1>;
                        xlnx,pmp-addr22 = <0x0>;
                        xlnx,lmb-data-size = <0x20>;
                        xlnx,lockstep-select = <0x0>;
                        xlnx,pmp-addr23 = <0x0>;
                        timebase-frequency = <0x5f5dd19>;
                        xlnx,pmp-addr24 = <0x0>;
                        xlnx,dcache-data-width = <0x0>;
                        xlnx,icache-force-tag-lutram = <0x0>;
                        xlnx,pmp-addr25 = <0x0>;
                        xlnx,pmp-addr26 = <0x0>;
                        xlnx,use-branch-target-cache = <0x0>;
                        xlnx,pmp-addr27 = <0x0>;
                        xlnx,number-of-pc-brk = <0x1>;
                        xlnx,pmp-addr28 = <0x0>;
                        xlnx,imprecise-exceptions = <0x0>;
                        xlnx,pmp-addr29 = <0x0>;
                        xlnx,pmp-addr30 = <0x0>;
                        xlnx,pmp-addr31 = <0x0>;
                        xlnx,pmp-addr32 = <0x0>;
                        model = "microblaze_riscv,1.0";
                        xlnx,pmp-addr33 = <0x0>;
                        xlnx,pmp-addr34 = <0x0>;
                        xlnx,pmp-addr35 = <0x0>;
                        xlnx,pmp-addr36 = <0x0>;
                        d-cache-highaddr = <0xffffffff>;
                        xlnx,optimization = <0x0>;
                        xlnx,pmp-addr37 = <0x0>;
                        xlnx,pmp-addr38 = <0x0>;
                        xlnx,pmp-addr39 = <0x0>;
                        xlnx,pmp-addr40 = <0x0>;
                        xlnx,pmp-addr41 = <0x0>;
                        xlnx,d-lmb-mon = <0x0>;
                        xlnx,pmp-addr42 = <0x0>;
                        xlnx,pmp-addr43 = <0x0>;
                        xlnx,pmp-addr44 = <0x0>;
                        xlnx,pmp-addr45 = <0x0>;
                        xlnx,pmp-addr46 = <0x0>;
                        xlnx,pmp-addr47 = <0x0>;
                        xlnx,pmp-addr48 = <0x0>;
                        xlnx,fault-tolerant = <0x0>;
                        xlnx,pmp-addr49 = <0x0>;
                        xlnx,pmp-addr50 = <0x0>;
                        xlnx,pmp-addr51 = <0x0>;
                        xlnx,pmp-enhancements = <0x0>;
                        d-cache-line-size = <0x10>;
                        xlnx,mmu-privileged-instr = <0x0>;
                        xlnx,pmp-addr52 = <0x0>;
                        clock-frequency = <0x5f5dd19>;
                        xlnx,pmp-addr53 = <0x0>;
                        xlnx,pmp-addr54 = <0x0>;
                        xlnx,pmp-addr55 = <0x0>;
                        xlnx,i-lmb-protocol = <0x0>;
                        xlnx,pmp-addr56 = <0x0>;
                        xlnx,pmp-addr57 = <0x0>;
                        xlnx,dp-axi-mon = <0x0>;
                        xlnx,pmp-addr58 = <0x0>;
                        xlnx,pmp-addr59 = <0x0>;
                        xlnx,pmp-addr60 = <0x0>;
                        xlnx,pmp-addr61 = <0x0>;
                        xlnx,pmp-addr62 = <0x0>;
                        xlnx,pmp-addr63 = <0x0>;
                        xlnx,debug-external-trace = <0x0>;
                        xlnx,addr-size = <0x20>;
                        xlnx,debug-event-counters = <0x0>;
                        xlnx,edk-iptype = "PROCESSOR";
                        xlnx,debug-latency-counters = <0x0>;
                        xlnx,interconnect = <0x2>;
                        xlnx,edge-is-positive = <0x1>;
                        xlnx,use-icache = <0x0>;
                        xlnx,async-wakeup = <0x3>;
                        xlnx,s-axi = <0x0>;
                        xlnx,use-ext-nm-brk = <0x0>;
                        xlnx,ic-axi-mon = <0x0>;
                        xlnx,archid = <0x1>;
                        xlnx,num-sync-ff-clk-irq = <0x1>;
                        xlnx,freq = <0x5f5dd19>;
                        xlnx,lockstep-master = <0x0>;
                        xlnx,pmp-cfg0 = <0x0>;
                        xlnx,pmp-cfg1 = <0x0>;
                        xlnx,iaddr-size = <0x20>;
                        xlnx,interrupt-mon = <0x0>;
                        xlnx,pmp-cfg2 = <0x0>;
                        xlnx,number-of-wr-addr-brk = <0x0>;
                        xlnx,pmp-cfg3 = <0x0>;
                        xlnx,pmp-cfg4 = <0x0>;
                        xlnx,use-interrupt = <0x1>;
                        xlnx,pmp-cfg5 = <0x0>;
                        xlnx,async-interrupt = <0x1>;
                        xlnx,pc-width = <0x20>;
                        xlnx,pmp-cfg6 = <0x0>;
                        xlnx,icache-victims = <0x0>;
                        xlnx,pmp-cfg7 = <0x0>;
                        xlnx,pmp-cfg8 = <0x0>;
                        xlnx,pmp-cfg9 = <0x0>;
                        xlnx,use-bitman-a = <0x0>;
                        xlnx,use-bitman-b = <0x0>;
                        xlnx,use-bitman-c = <0x0>;
                        xlnx,i-lmb-mon = <0x0>;
                        xlnx,dcache-byte-size = <0x4000>;
                        xlnx,data-size = <0x20>;
                        compatible = "xlnx,microblaze-riscv-1.0", "xlnx,microblaze_riscv";
                        xlnx,pmp-debug-inhibit = <0x0>;
                        xlnx,fsl-exception = <0x0>;
                        xlnx,dcache-use-writeback = <0x0>;
                        device_type = "cpu";
                        xlnx,impid = <0x1>;
                        xlnx,use-bitman-s = <0x0>;
                        xlnx,base-vectors = <0x90080000>;
                        xlnx,icache-line-len = <0x4>;
                        xlnx,use-barrel = <0x1>;
                        xlnx,misaligned-exceptions = <0x1>;
                        xlnx,piaddr-size = <0x20>;
                        xlnx,use-bitman = <0x0>;
                        xlnx,dcache-line-len = <0x4>;
                        xlnx,num-sync-ff-clk = <0x2>;
                        xlnx,memory-ip-list = "psu_ddr_0_memory", "psu_ddr_0_memory", "psu_ocm_ram_0_memory", "psu_ocm_ram_0_memory", "psu_r5_1_btcm_global_memory", "psu_r5_1_btcm_global_memory", "psu_r5_1_atcm_global_memory", "psu_r5_1_atcm_global_memory", "psu_r5_0_btcm_global_memory", "psu_r5_0_btcm_global_memory", "psu_r5_0_atcm_global_memory", "psu_r5_0_atcm_global_memory";
                        xlnx,number-of-rd-addr-brk = <0x0>;
                        xlnx,lockstep-slave = <0x0>;
                        xlnx,use-counters = <0x1>;
                        interrupt-handle = <0x9e>;
                        xlnx,pmp-cfg10 = <0x0>;
                        xlnx,pmp-cfg11 = <0x0>;
                        xlnx,debug-profile-size = <0x0>;
                        xlnx,pmp-cfg12 = <0x0>;
                        xlnx,pmp-cfg13 = <0x0>;
                        xlnx,pmp-cfg14 = <0x0>;
                        xlnx,pmp-cfg15 = <0x0>;
                        xlnx,debug-counter-width = <0x40>;
                        xlnx,icache-data-width = <0x0>;
                        xlnx,ip-name = "microblaze_riscv";
                        xlnx,ip-axi-mon = <0x0>;
                        xlnx,d-lmb-protocol = <0x0>;
                        xlnx,trace = <0x0>;
                        xlnx,ill-instr-exception = <0x2>;
                        xlnx,debug-trace-size = <0x0>;
                        xlnx,pmp-granularity = <0x2>;
                        xlnx,num-sync-ff-dbg-trace-clk = <0x2>;
                        xlnx,ecc-use-ce-exception = <0x0>;
                        xlnx,num-sync-ff-clk-debug = <0x2>;
                        xlnx,use-atomic = <0x0>;
                        xlnx,g-template-list = <0x0>;
                        xlnx,hartid = <0x0>;
                        xlnx,use-fpu = <0x0>;
                        xlnx,use-non-secure = <0x0>;
                        d-cache-baseaddr = <0x80000000>;
                        xlnx,use-compression = <0x0>;
                        xlnx,instr-size = <0x20>;
                        xlnx,fsl-links = <0x0>;
                        xlnx,dcache-victims = <0x0>;
                        xlnx,pmp-read-only = <0x0>;
                        phandle = <0x114>;
                };
        };

        clock: clocks {
                #address-cells = <0x1>;
                #size-cells = <0x0>;
                phandle = <0x115>;

                clk_cpu_0: clk_cpu@0 {
                        compatible = "fixed-clock";
                        reg = <0x0>;
                        clock-frequency = <0x5f5dd19>;
                        clock-output-names = "clk_cpu";
                        #clock-cells = <0x0>;
                        phandle = <0x116>;
                };
        };

        amba_pl: amba_pl {
                ranges;
                compatible = "simple-bus";
                #address-cells = <0x2>;
                #size-cells = <0x2>;
                firmware-name = "byotee_riscv_new.bit.bin";
                phandle = <0xa0>;

                axi_intc_0: interrupt-controller@80010000 {
                        #interrupt-cells = <0x2>;
                        xlnx,sense-of-irq-edge-type = "Rising";
                        xlnx,edk-special = "INTR_CTRL";
                        xlnx,kind-of-intr = <0x0>;
                        xlnx,kind-of-edge = <0xffffffff>;
                        xlnx,irq-is-level = <0x1>;
                        xlnx,has-ivr = <0x0>;
                        compatible = "xlnx,axi-intc-4.1", "xlnx,xps-intc-1.00.a";
                        xlnx,disable-synchronizers = <0x0>;
                        xlnx,kind-of-lvl = <0xffffffff>;
                        xlnx,ivar-reset-value = <0x10>;
                        xlnx,irq-active = <0x1>;
                        xlnx,en-cascade-mode = <0x0>;
                        xlnx,ip-name = "axi_intc";
                        xlnx,has-ilr = <0x0>;
                        reg = <0x0 0x80010000 0x0 0x10000>;
                        xlnx,addr-width = <0x20>;
                        clocks = <&zynqmp_clk 0x47>;
                        xlnx,s-axi-aclk-freq-mhz = <0x5f5dd19>;
                        xlnx,num-sw-intr = <0x0>;
                        xlnx,irq-connection = <0x0>;
                        xlnx,num-intr-inputs = <0x1>;
                        xlnx,has-sie = <0x0>;
                        xlnx,enable-async = <0x0>;
                        xlnx,has-cie = <0x0>;
                        xlnx,num-sync-ff = <0x2>;
                        xlnx,edk-iptype = "PERIPHERAL";
                        xlnx,mb-clk-not-connected = <0x1>;
                        xlnx,has-ipr = <0x1>;
                        xlnx,sense-of-irq-level-type = "Active_High";
                        xlnx,cascade-master = <0x0>;
                        xlnx,processor-clk-freq-mhz = <0x64>;
                        status = "okay";
                        xlnx,is-fast = <0x0>;
                        clock-names = "s_axi_aclk";
                        xlnx,has-fast = <0x0>;
                        xlnx,ivar-rst-val = <0x10>;
                        interrupt-controller;
                        xlnx,async-intr = <0xfffffffe>;
                        xlnx,name = "axi_intc_0";
                        phandle = <0x9e>;
                };

                axi_gpio_1: gpio@80000000 {
                        xlnx,gpio-board-interface = "Custom";
                        compatible = "xlnx,axi-gpio-2.0", "xlnx,xps-gpio-1.00.a";
                        xlnx,all-outputs = <0x0>;
                        #gpio-cells = <0x2>;
                        xlnx,gpio-width = <0x8>;
                        xlnx,dout-default = <0x0>;
                        xlnx,is-dual = <0x0>;
                        xlnx,ip-name = "axi_gpio";
                        xlnx,tri-default-2 = <0xffffffff>;
                        reg = <0x0 0x80000000 0x0 0x10000>;
                        xlnx,all-inputs-2 = <0x0>;
                        clocks = <&zynqmp_clk 0x47>;
                        xlnx,all-outputs-2 = <0x0>;
                        gpio-controller;
                        xlnx,interrupt-present = <0x0>;
                        xlnx,gpio2-board-interface = "Custom";
                        xlnx,edk-iptype = "PERIPHERAL";
                        xlnx,dout-default-2 = <0x0>;
                        status = "okay";
                        xlnx,gpio2-width = <0x20>;
                        clock-names = "s_axi_aclk";
                        xlnx,tri-default = <0xffffffff>;
                        xlnx,name = "axi_gpio_1";
                        xlnx,all-inputs = <0x0>;
                        phandle = <0x9d>;
                };

                microblaze_riscv_0_local_memory_dlmb_bram_if_cntlr: lmb_bram_if_cntlr@0 {
                        xlnx,edk-special = "BRAM_CTRL";
                        xlnx,write-access = <0x2>;
                        compatible = "xlnx,lmb-bram-if-cntlr-4.0", "xlnx,axi-bram-ctrl";
                        xlnx,ecc-onoff-register = <0x0>;
                        xlnx,ecc-onoff-reset-value = <0x1>;
                        xlnx,s-axi-ctrl-protocol = "AXI4LITE";
                        xlnx,mask = <0x91000000>;
                        xlnx,mask1 = <0x800000>;
                        xlnx,mask2 = <0x800000>;
                        xlnx,fault-inject = <0x0>;
                        xlnx,mask3 = <0x800000>;
                        xlnx,ip-name = "lmb_bram_if_cntlr";
                        xlnx,arbitration = <0x0>;
                        xlnx,num-lmb = <0x1>;
                        xlnx,mask4 = <0x800000>;
                        reg = <0x0 0x90000000 0x0 0x40000>;
                        xlnx,s-axi-ctrl-addr-width = <0x20>;
                        xlnx,mask5 = <0x800000>;
                        xlnx,ecc-status-registers = <0x0>;
                        xlnx,mask6 = <0x800000>;
                        xlnx,lmb-protocol = <0x0>;
                        xlnx,ce-counter-width = <0x0>;
                        xlnx,mask7 = <0x800000>;
                        xlnx,ecc = <0x0>;
                        xlnx,edk-iptype = "PERIPHERAL";
                        xlnx,lmb-dwidth = <0x20>;
                        xlnx,interconnect = <0x0>;
                        xlnx,ce-failing-registers = <0x0>;
                        xlnx,ue-failing-registers = <0x0>;
                        status = "okay";
                        xlnx,data-width = <0x20>;
                        xlnx,s-axi-ctrl-data-width = <0x20>;
                        xlnx,bram-awidth = <0x20>;
                        xlnx,lmb-awidth = <0x20>;
                        xlnx,name = "microblaze_riscv_0_local_memory_dlmb_bram_if_cntlr";
                        phandle = <0x9a>;
                };

                microblaze_riscv_0_local_memory_ilmb_bram_if_cntlr: lmb_bram_if_cntlr@1 {
                        xlnx,edk-special = "BRAM_CTRL";
                        xlnx,write-access = <0x2>;
                        compatible = "xlnx,lmb-bram-if-cntlr-4.0", "xlnx,axi-bram-ctrl";
                        xlnx,ecc-onoff-register = <0x0>;
                        xlnx,ecc-onoff-reset-value = <0x1>;
                        xlnx,s-axi-ctrl-protocol = "AXI4LITE";
                        xlnx,mask = <0xc0080000>;
                        xlnx,mask1 = <0x800000>;
                        xlnx,mask2 = <0x800000>;
                        xlnx,fault-inject = <0x0>;
                        xlnx,mask3 = <0x800000>;
                        xlnx,ip-name = "lmb_bram_if_cntlr";
                        xlnx,arbitration = <0x0>;
                        xlnx,num-lmb = <0x1>;
                        xlnx,mask4 = <0x800000>;
                        reg = <0x0 0x90080000 0x0 0x40000>;
                        xlnx,s-axi-ctrl-addr-width = <0x20>;
                        xlnx,mask5 = <0x800000>;
                        xlnx,ecc-status-registers = <0x0>;
                        xlnx,mask6 = <0x800000>;
                        xlnx,lmb-protocol = <0x0>;
                        xlnx,ce-counter-width = <0x0>;
                        xlnx,mask7 = <0x800000>;
                        xlnx,ecc = <0x0>;
                        xlnx,edk-iptype = "PERIPHERAL";
                        xlnx,lmb-dwidth = <0x20>;
                        xlnx,interconnect = <0x0>;
                        xlnx,ce-failing-registers = <0x0>;
                        xlnx,ue-failing-registers = <0x0>;
                        status = "okay";
                        xlnx,data-width = <0x20>;
                        xlnx,s-axi-ctrl-data-width = <0x20>;
                        xlnx,bram-awidth = <0x20>;
                        xlnx,lmb-awidth = <0x20>;
                        xlnx,name = "microblaze_riscv_0_local_memory_ilmb_bram_if_cntlr";
                        phandle = <0x9c>;
                };

                pl_ps_intr: gpio@80020000 {
                        xlnx,gpio-board-interface = "Custom";
                        compatible = "xlnx,axi-gpio-2.0", "xlnx,xps-gpio-1.00.a";
                        xlnx,all-outputs = <0x1>;
                        #gpio-cells = <0x2>;
                        xlnx,gpio-width = <0x1>;
                        xlnx,dout-default = <0x0>;
                        xlnx,is-dual = <0x0>;
                        xlnx,ip-name = "axi_gpio";
                        xlnx,tri-default-2 = <0xffffffff>;
                        reg = <0x0 0x80020000 0x0 0x10000>;
                        xlnx,all-inputs-2 = <0x0>;
                        clocks = <&zynqmp_clk 0x47>;
                        xlnx,all-outputs-2 = <0x0>;
                        gpio-controller;
                        xlnx,interrupt-present = <0x0>;
                        xlnx,gpio2-board-interface = "Custom";
                        xlnx,edk-iptype = "PERIPHERAL";
                        xlnx,dout-default-2 = <0x0>;
                        status = "okay";
                        xlnx,gpio2-width = <0x20>;
                        clock-names = "s_axi_aclk";
                        xlnx,tri-default = <0xffffffff>;
                        xlnx,name = "pl_ps_intr";
                        xlnx,all-inputs = <0x0>;
                        phandle = <0x9f>;
                };
        };

        microblaze_riscv_0_local_memory_dlmb_bram_if_cntlr_memory: memory@90000000 {
                compatible = "xlnx,lmb-bram-if-cntlr-4.0";
                xlnx,ip-name = "lmb_bram_if_cntlr";
                device_type = "memory";
                memory_type = "memory";
                reg = <0x0 0x90000000 0x0 0x40000>;
                phandle = <0x99>;
        };

        microblaze_riscv_0_local_memory_ilmb_bram_if_cntlr_memory: memory@90080000 {
                compatible = "xlnx,lmb-bram-if-cntlr-4.0";
                xlnx,ip-name = "lmb_bram_if_cntlr";
                device_type = "memory";
                memory_type = "memory";
                reg = <0x0 0x90080000 0x0 0x40000>;
                phandle = <0x9b>;
        };

        psu_ocm_ram_0_memory: memory@FFFC0000 {
                compatible = "xlnx,psu-ocm-ram-0-1.0", "mmio-sram";
                xlnx,ip-name = "psu_ocm_ram_0";
                device_type = "memory";
                memory_type = "memory";
                reg = <0x0 0xfffc0000 0x0 0x40000>;
                phandle = <0x7>;
        };

        psu_ddr_0_memory: memory@0 {
                compatible = "xlnx,psu-ddr-1.0";
                xlnx,ip-name = "psu_ddr";
                device_type = "memory";
                memory_type = "memory";
                reg = <0x0 0x0 0x0 0x40000000 0x0 0x60000000 0x0 0x1ff00000>;
                phandle = <0x9>;
        };

        psu_qspi_linear_0_memory: memory@c0000000 {
                compatible = "xlnx,psu-qspi-linear-1.0-memory";
                xlnx,ip-name = "psu_qspi_linear";
                device_type = "memory";
                memory_type = "linear_flash";
                reg = <0x0 0xc0000000 0x0 0x10000000>;
                phandle = <0xa>;
        };

        chosen {
                bootargs = "earlycon console=ttyPS0,115200 clk_ignore_unused init_fatal_sh=1";
                stdout-path = "serial0:115200n8";
        };

        aliases {
                serial0 = "/axi/serial@ff000000";
                spi0 = "/axi/spi@ff0f0000";
                serial1 = "/axi/serial@ff010000";
                serial2 = "/axi/coresight@fe800000";
                i2c0 = "/axi/i2c@ff030000";
                ethernet0 = "/axi/ethernet@ff0e0000";
        };

        __symbols__ {
                cpu_opp_table = "/opp-table-cpu";
                zynqmp_ipi = "/zynqmp-ipi";
                ipi_mailbox_pmu1 = "/zynqmp-ipi/mailbox@ff9905c0";
                zynqmp_firmware = "/firmware/zynqmp-firmware";
                zynqmp_power = "/firmware/zynqmp-firmware/power-management";
                soc_revision = "/firmware/zynqmp-firmware/soc-nvmem/nvmem-layout/soc-revision@0";
                efuse_dna = "/firmware/zynqmp-firmware/soc-nvmem/nvmem-layout/efuse-dna@c";
                efuse_usr0 = "/firmware/zynqmp-firmware/soc-nvmem/nvmem-layout/efuse-usr0@20";
                efuse_usr1 = "/firmware/zynqmp-firmware/soc-nvmem/nvmem-layout/efuse-usr1@24";
                efuse_usr2 = "/firmware/zynqmp-firmware/soc-nvmem/nvmem-layout/efuse-usr2@28";
                efuse_usr3 = "/firmware/zynqmp-firmware/soc-nvmem/nvmem-layout/efuse-usr3@2c";
                efuse_usr4 = "/firmware/zynqmp-firmware/soc-nvmem/nvmem-layout/efuse-usr4@30";
                efuse_usr5 = "/firmware/zynqmp-firmware/soc-nvmem/nvmem-layout/efuse-usr5@34";
                efuse_usr6 = "/firmware/zynqmp-firmware/soc-nvmem/nvmem-layout/efuse-usr6@38";
                efuse_usr7 = "/firmware/zynqmp-firmware/soc-nvmem/nvmem-layout/efuse-usr7@3c";
                efuse_miscusr = "/firmware/zynqmp-firmware/soc-nvmem/nvmem-layout/efuse-miscusr@40";
                efuse_chash = "/firmware/zynqmp-firmware/soc-nvmem/nvmem-layout/efuse-chash@50";
                efuse_pufmisc = "/firmware/zynqmp-firmware/soc-nvmem/nvmem-layout/efuse-pufmisc@54";
                efuse_sec = "/firmware/zynqmp-firmware/soc-nvmem/nvmem-layout/efuse-sec@58";
                efuse_spkid = "/firmware/zynqmp-firmware/soc-nvmem/nvmem-layout/efuse-spkid@5c";
                efuse_aeskey = "/firmware/zynqmp-firmware/soc-nvmem/nvmem-layout/efuse-aeskey@60";
                efuse_ppk0hash = "/firmware/zynqmp-firmware/soc-nvmem/nvmem-layout/efuse-ppk0hash@a0";
                efuse_ppk1hash = "/firmware/zynqmp-firmware/soc-nvmem/nvmem-layout/efuse-ppk1hash@d0";
                efuse_pufuser = "/firmware/zynqmp-firmware/soc-nvmem/nvmem-layout/efuse-pufuser@100";
                zynqmp_pcap = "/firmware/zynqmp-firmware/pcap";
                modepin_gpio = "/firmware/zynqmp-firmware/gpio";
                zynqmp_clk = "/firmware/zynqmp-firmware/clock-controller";
                fpga_full = "/fpga-region";
                tsens_apu = "/thermal-sensor-apu";
                tsens_rpu = "/thermal-sensor-rpu";
                tsens_pl = "/thermal-sensor-pl";
                apu_passive = "/thermal-zones/apu-thermal/trips/passive";
                apu_critical = "/thermal-zones/apu-thermal/trips/critical";
                amba_apu = "/apu-bus";
                amba_rpu = "/rpu-bus";
                amba = "/axi";
                imux = "/axi/interrupt-multiplex";
                psu_cortexa53_0_debug = "/axi/debug@fec10000";
                psu_cortexa53_1_debug = "/axi/debug@fed10000";
                psu_cortexa53_2_debug = "/axi/debug@fee10000";
                psu_cortexa53_3_debug = "/axi/debug@fef10000";
                lpd_dma_chan1 = "/axi/dma-controller@ffa80000";
                lpd_dma_chan2 = "/axi/dma-controller@ffa90000";
                lpd_dma_chan3 = "/axi/dma-controller@ffaa0000";
                lpd_dma_chan4 = "/axi/dma-controller@ffab0000";
                lpd_dma_chan5 = "/axi/dma-controller@ffac0000";
                lpd_dma_chan6 = "/axi/dma-controller@ffad0000";
                lpd_dma_chan7 = "/axi/dma-controller@ffae0000";
                lpd_dma_chan8 = "/axi/dma-controller@ffaf0000";
                gem3 = "/axi/ethernet@ff0e0000";
                gpio = "/axi/gpio@ff0a0000";
                i2c1 = "/axi/i2c@ff030000";
                ocm = "/axi/memory-controller@ff960000";
                perf_monitor_ocm = "/axi/perf-monitor@ffa00000";
                perf_monitor_lpd = "/axi/perf-monitor@ffa10000";
                qspi = "/axi/spi@ff0f0000";
                rtc = "/axi/rtc@ffa60000";
                sdhci0 = "/axi/mmc@ff160000";
                sdhci1 = "/axi/mmc@ff170000";
                spi0 = "/axi/spi@ff040000";
                uart0 = "/axi/serial@ff000000";
                uart1 = "/axi/serial@ff010000";
                usb0 = "/axi/usb@ff9d0000";
                lpd_watchdog = "/axi/watchdog@ff150000";
                xilinx_ams = "/axi/ams@ffa50000";
                csudma_0 = "/axi/dma@ffc80000";
                psu_r5_tcm_ram_global = "/axi/psu_r5_tcm_ram@ffe00000";
                psu_r5_tcm_ram_0 = "/axi/psu_r5_tcm_ram@0";
                psu_r5_1_btcm = "/axi/psu_r5_1_btcm@20000";
                psu_r5_1_btcm_global = "/axi/psu_r5_1_btcm_global@ffeb0000";
                psu_r5_1_atcm = "/axi/psu_r5_1_atcm@0";
                psu_r5_1_atcm_global = "/axi/psu_r5_1_atcm_global@ffe90000";
                psu_r5_0_btcm_lockstep = "/axi/psu_r5_0_btcm_lockstep@ffe30000";
                psu_r5_0_btcm = "/axi/psu_r5_0_btcm@20000";
                psu_r5_0_btcm_global = "/axi/psu_r5_0_btcm_global@ffe20000";
                psu_r5_0_atcm_lockstep = "/axi/psu_r5_0_atcm_lockstep@ffe10000";
                psu_r5_0_atcm = "/axi/psu_r5_0_atcm@0";
                psu_r5_0_atcm_global = "/axi/psu_r5_0_atcm_global@ffe00000";
                psu_pmu_global_0 = "/axi/psu_pmu_global_0@ffd80000";
                psu_mbistjtag = "/axi/psu_mbistjtag@ffcf0000";
                psu_rsa = "/axi/psu_rsa@ffce0000";
                psu_efuse = "/axi/psu_efuse@ffcc0000";
                psu_csu_0 = "/axi/psu_csu@ffca0000";
                psu_ocm_xmpu_cfg = "/axi/psu_ocm_xmpu_cfg@ffa70000";
                psu_lpd_xppu_sink = "/axi/psu_lpd_xppu_sink@ff9c0000";
                psu_afi_6 = "/axi/psu_afi@ff9b0000";
                psu_rpu = "/axi/psu_rpu@ff9a0000";
                psu_crl_apb = "/axi/psu_crl_apb@ff5e0000";
                psu_lpd_slcr_secure = "/axi/psu_lpd_slcr_secure@ff4b0000";
                psu_lpd_slcr = "/axi/psu_lpd_slcr@ff410000";
                psu_ctrl_ipi = "/axi/PERIPHERAL@ff380000";
                psu_message_buffers = "/axi/PERIPHERAL@ff990000";
                psu_iou_scntrs = "/axi/psu_iou_scntrs@ff260000";
                psu_iou_scntr = "/axi/psu_iou_scntr@ff250000";
                psu_iousecure_slcr = "/axi/psu_iousecure_slcr@ff240000";
                psu_iouslcr_0 = "/axi/psu_iouslcr@ff180000";
                psu_qspi_linear_0 = "/axi/psu_qspi_linear@c0000000";
                amba_xppu = "/indirect-bus@1";
                lpd_xppu = "/indirect-bus@1/xppu@ff980000";
                binman = "/binman";
                pss_ref_clk = "/pss-ref-clk";
                video_clk = "/video-clk";
                pss_alt_ref_clk = "/pss-alt-ref-clk";
                gt_crx_ref_clk = "/gt-crx-ref-clk";
                aux_ref_clk = "/aux-ref-clk";
                cpus_microblaze_riscv_0 = "/cpus_microblaze_riscv@0";
                microblaze_riscv_0 = "/cpus_microblaze_riscv@0/cpu@0";
                clock = "/clocks";
                clk_cpu_0 = "/clocks/clk_cpu@0";
                amba_pl = "/amba_pl";
                axi_intc_0 = "/amba_pl/interrupt-controller@80010000";
                axi_gpio_1 = "/amba_pl/gpio@80000000";
                microblaze_riscv_0_local_memory_dlmb_bram_if_cntlr = "/amba_pl/lmb_bram_if_cntlr@0";
                microblaze_riscv_0_local_memory_ilmb_bram_if_cntlr = "/amba_pl/lmb_bram_if_cntlr@1";
                pl_ps_intr = "/amba_pl/gpio@80020000";
                microblaze_riscv_0_local_memory_dlmb_bram_if_cntlr_memory = "/memory@90000000";
                microblaze_riscv_0_local_memory_ilmb_bram_if_cntlr_memory = "/memory@90080000";
                psu_ocm_ram_0_memory = "/memory@FFFC0000";
                psu_ddr_0_memory = "/memory@0";
                psu_qspi_linear_0_memory = "/memory@c0000000";
        };
};
